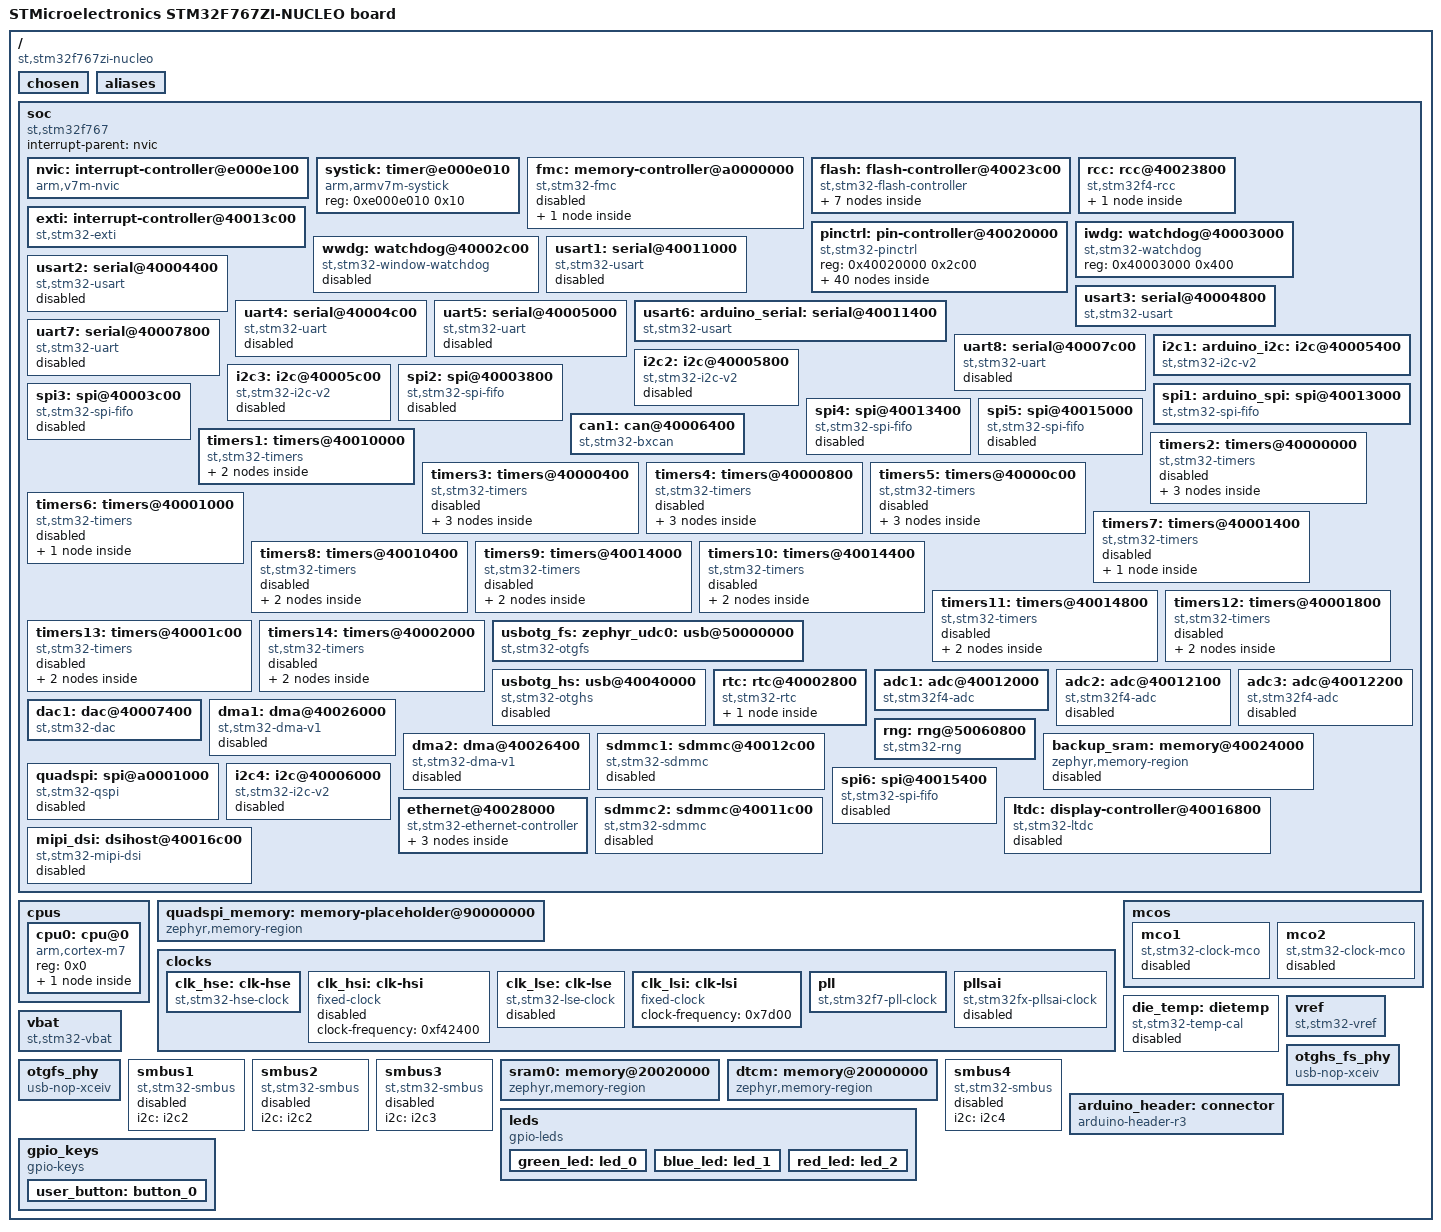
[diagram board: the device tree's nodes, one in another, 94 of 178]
/dts-v1/;

/* node '/' defined in zephyr\dts\common\skeleton.dtsi:9 */
/ {
	#address-cells = < 0x1 >;                              /* in zephyr\dts\common\skeleton.dtsi:10 */
	#size-cells = < 0x1 >;                                 /* in zephyr\dts\common\skeleton.dtsi:11 */
	model = "STMicroelectronics STM32F767ZI-NUCLEO board"; /* in zephyr\boards\st\nucleo_f767zi\nucleo_f767zi.dts:21 */
	compatible = "st,stm32f767zi-nucleo";                  /* in zephyr\boards\st\nucleo_f767zi\nucleo_f767zi.dts:22 */

	/* node '/chosen' defined in zephyr\dts\common\skeleton.dtsi:13 */
	chosen {
		zephyr,entropy = &rng;                    /* in zephyr\dts\arm\st\f7\stm32f7.dtsi:27 */
		zephyr,flash-controller = &flash;         /* in zephyr\dts\arm\st\f7\stm32f7.dtsi:28 */
		zephyr,console = &usart3;                 /* in zephyr\boards\st\nucleo_f767zi\nucleo_f767zi.dts:25 */
		zephyr,shell-uart = &usart3;              /* in zephyr\boards\st\nucleo_f767zi\nucleo_f767zi.dts:26 */
		zephyr,sram = &sram0;                     /* in zephyr\boards\st\nucleo_f767zi\nucleo_f767zi.dts:27 */
		zephyr,flash = &flash0;                   /* in zephyr\boards\st\nucleo_f767zi\nucleo_f767zi.dts:28 */
		zephyr,code-partition = &slot0_partition; /* in zephyr\boards\st\nucleo_f767zi\nucleo_f767zi.dts:29 */
		zephyr,dtcm = &dtcm;                      /* in zephyr\boards\st\nucleo_f767zi\nucleo_f767zi.dts:30 */
		zephyr,canbus = &can1;                    /* in zephyr\boards\st\nucleo_f767zi\nucleo_f767zi.dts:31 */
	};

	/* node '/aliases' defined in zephyr\dts\common\skeleton.dtsi:15 */
	aliases {
		led0 = &green_led;    /* in zephyr\boards\st\nucleo_f767zi\nucleo_f767zi.dts:64 */
		led1 = &blue_led;     /* in zephyr\boards\st\nucleo_f767zi\nucleo_f767zi.dts:65 */
		led2 = &red_led;      /* in zephyr\boards\st\nucleo_f767zi\nucleo_f767zi.dts:66 */
		sw0 = &user_button;   /* in zephyr\boards\st\nucleo_f767zi\nucleo_f767zi.dts:67 */
		watchdog0 = &iwdg;    /* in zephyr\boards\st\nucleo_f767zi\nucleo_f767zi.dts:68 */
		volt-sensor0 = &vref; /* in zephyr\boards\st\nucleo_f767zi\nucleo_f767zi.dts:69 */
		volt-sensor1 = &vbat; /* in zephyr\boards\st\nucleo_f767zi\nucleo_f767zi.dts:70 */
	};

	/* node '/soc' defined in zephyr\dts\arm\armv7-m.dtsi:6 */
	soc {
		#address-cells = < 0x1 >;     /* in zephyr\dts\arm\armv7-m.dtsi:7 */
		#size-cells = < 0x1 >;        /* in zephyr\dts\arm\armv7-m.dtsi:8 */
		interrupt-parent = < &nvic >; /* in zephyr\dts\arm\armv7-m.dtsi:10 */
		ranges;                       /* in zephyr\dts\arm\armv7-m.dtsi:11 */
		compatible = "st,stm32f767",
		             "st,stm32f7",
		             "simple-bus";    /* in zephyr\dts\arm\st\f7\stm32f767.dtsi:13 */

		/* node '/soc/interrupt-controller@e000e100' defined in zephyr\dts\arm\armv7-m.dtsi:13 */
		nvic: interrupt-controller@e000e100 {
			#address-cells = < 0x1 >;            /* in zephyr\dts\arm\armv7-m.dtsi:14 */
			compatible = "arm,v7m-nvic";         /* in zephyr\dts\arm\armv7-m.dtsi:15 */
			reg = < 0xe000e100 0xc00 >;          /* in zephyr\dts\arm\armv7-m.dtsi:16 */
			interrupt-controller;                /* in zephyr\dts\arm\armv7-m.dtsi:17 */
			#interrupt-cells = < 0x2 >;          /* in zephyr\dts\arm\armv7-m.dtsi:18 */
			arm,num-irq-priority-bits = < 0x4 >; /* in zephyr\dts\arm\st\f7\stm32f7.dtsi:991 */
			phandle = < 0x1 >;                   /* in zephyr\dts\arm\armv7-m.dtsi:10 */
		};

		/* node '/soc/timer@e000e010' defined in zephyr\dts\arm\armv7-m.dtsi:21 */
		systick: timer@e000e010 {
			compatible = "arm,armv7m-systick"; /* in zephyr\dts\arm\armv7-m.dtsi:22 */
			reg = < 0xe000e010 0x10 >;         /* in zephyr\dts\arm\armv7-m.dtsi:23 */
		};

		/* node '/soc/memory-controller@a0000000' defined in zephyr\dts\arm\st\f7\stm32f7.dtsi:111 */
		fmc: memory-controller@a0000000 {
			compatible = "st,stm32-fmc"; /* in zephyr\dts\arm\st\f7\stm32f7.dtsi:112 */
			reg = < 0xa0000000 0x400 >;  /* in zephyr\dts\arm\st\f7\stm32f7.dtsi:113 */
			clocks = < &rcc 0x38 0x1 >;  /* in zephyr\dts\arm\st\f7\stm32f7.dtsi:114 */
			status = "disabled";         /* in zephyr\dts\arm\st\f7\stm32f7.dtsi:115 */

			/* node '/soc/memory-controller@a0000000/sdram' defined in zephyr\dts\arm\st\f7\stm32f7.dtsi:117 */
			sdram: sdram {
				compatible = "st,stm32-fmc-sdram"; /* in zephyr\dts\arm\st\f7\stm32f7.dtsi:118 */
				#address-cells = < 0x1 >;          /* in zephyr\dts\arm\st\f7\stm32f7.dtsi:119 */
				#size-cells = < 0x0 >;             /* in zephyr\dts\arm\st\f7\stm32f7.dtsi:120 */
				status = "disabled";               /* in zephyr\dts\arm\st\f7\stm32f7.dtsi:121 */
			};
		};

		/* node '/soc/flash-controller@40023c00' defined in zephyr\dts\arm\st\f7\stm32f7.dtsi:125 */
		flash: flash-controller@40023c00 {
			compatible = "st,stm32-flash-controller",
			             "st,stm32f7-flash-controller"; /* in zephyr\dts\arm\st\f7\stm32f7.dtsi:126 */
			reg = < 0x40023c00 0x400 >;                 /* in zephyr\dts\arm\st\f7\stm32f7.dtsi:127 */
			interrupts = < 0x4 0x0 >;                   /* in zephyr\dts\arm\st\f7\stm32f7.dtsi:128 */
			#address-cells = < 0x1 >;                   /* in zephyr\dts\arm\st\f7\stm32f7.dtsi:130 */
			#size-cells = < 0x1 >;                      /* in zephyr\dts\arm\st\f7\stm32f7.dtsi:131 */

			/* node '/soc/flash-controller@40023c00/flash@8000000' defined in zephyr\dts\arm\st\f7\stm32f7.dtsi:133 */
			flash0: flash@8000000 {
				compatible = "st,stm32-nv-flash",
				             "soc-nv-flash";      /* in zephyr\dts\arm\st\f7\stm32f7.dtsi:134 */
				write-block-size = < 0x1 >;       /* in zephyr\dts\arm\st\f7\stm32f7.dtsi:136 */
				max-erase-time = < 0xfa0 >;       /* in zephyr\dts\arm\st\f7\stm32f7.dtsi:138 */
				reg = < 0x8000000 0x200000 >;     /* in zephyr\dts\arm\st\f7\stm32f767Xi.dtsi:14 */

				/* node '/soc/flash-controller@40023c00/flash@8000000/partitions' defined in zephyr\boards\st\nucleo_f767zi\nucleo_f767zi.dts:219 */
				partitions {
					compatible = "fixed-partitions"; /* in zephyr\boards\st\nucleo_f767zi\nucleo_f767zi.dts:220 */
					#address-cells = < 0x1 >;        /* in zephyr\boards\st\nucleo_f767zi\nucleo_f767zi.dts:221 */
					#size-cells = < 0x1 >;           /* in zephyr\boards\st\nucleo_f767zi\nucleo_f767zi.dts:222 */

					/* node '/soc/flash-controller@40023c00/flash@8000000/partitions/partition@0' defined in zephyr\boards\st\nucleo_f767zi\nucleo_f767zi.dts:228 */
					boot_partition: partition@0 {
						label = "mcuboot";     /* in zephyr\boards\st\nucleo_f767zi\nucleo_f767zi.dts:229 */
						reg = < 0x0 0x10000 >; /* in zephyr\boards\st\nucleo_f767zi\nucleo_f767zi.dts:230 */
						read-only;             /* in zephyr\boards\st\nucleo_f767zi\nucleo_f767zi.dts:231 */
					};

					/* node '/soc/flash-controller@40023c00/flash@8000000/partitions/partition@10000' defined in zephyr\boards\st\nucleo_f767zi\nucleo_f767zi.dts:239 */
					storage_partition: partition@10000 {
						label = "storage";         /* in zephyr\boards\st\nucleo_f767zi\nucleo_f767zi.dts:240 */
						reg = < 0x10000 0x10000 >; /* in zephyr\boards\st\nucleo_f767zi\nucleo_f767zi.dts:241 */
					};

					/* node '/soc/flash-controller@40023c00/flash@8000000/partitions/partition@40000' defined in zephyr\boards\st\nucleo_f767zi\nucleo_f767zi.dts:251 */
					slot0_partition: partition@40000 {
						label = "image-0";         /* in zephyr\boards\st\nucleo_f767zi\nucleo_f767zi.dts:252 */
						reg = < 0x40000 0xc0000 >; /* in zephyr\boards\st\nucleo_f767zi\nucleo_f767zi.dts:253 */
					};

					/* node '/soc/flash-controller@40023c00/flash@8000000/partitions/partition@100000' defined in zephyr\boards\st\nucleo_f767zi\nucleo_f767zi.dts:259 */
					slot1_partition: partition@100000 {
						label = "image-1";          /* in zephyr\boards\st\nucleo_f767zi\nucleo_f767zi.dts:260 */
						reg = < 0x100000 0xc0000 >; /* in zephyr\boards\st\nucleo_f767zi\nucleo_f767zi.dts:261 */
					};

					/* node '/soc/flash-controller@40023c00/flash@8000000/partitions/partition@1C0000' defined in zephyr\boards\st\nucleo_f767zi\nucleo_f767zi.dts:267 */
					scratch_partition: partition@1C0000 {
						label = "image-scratch";    /* in zephyr\boards\st\nucleo_f767zi\nucleo_f767zi.dts:268 */
						reg = < 0x1c0000 0x40000 >; /* in zephyr\boards\st\nucleo_f767zi\nucleo_f767zi.dts:269 */
					};
				};
			};
		};

		/* node '/soc/rcc@40023800' defined in zephyr\dts\arm\st\f7\stm32f7.dtsi:142 */
		rcc: rcc@40023800 {
			compatible = "st,stm32f4-rcc";   /* in zephyr\dts\arm\st\f7\stm32f7.dtsi:143 */
			#clock-cells = < 0x2 >;          /* in zephyr\dts\arm\st\f7\stm32f7.dtsi:144 */
			reg = < 0x40023800 0x400 >;      /* in zephyr\dts\arm\st\f7\stm32f7.dtsi:145 */
			clocks = < &pll >;               /* in zephyr\boards\st\nucleo_f767zi\nucleo_f767zi.dts:94 */
			clock-frequency = < 0xcdfe600 >; /* in zephyr\boards\st\nucleo_f767zi\nucleo_f767zi.dts:95 */
			ahb-prescaler = < 0x1 >;         /* in zephyr\boards\st\nucleo_f767zi\nucleo_f767zi.dts:96 */
			apb1-prescaler = < 0x4 >;        /* in zephyr\boards\st\nucleo_f767zi\nucleo_f767zi.dts:97 */
			apb2-prescaler = < 0x2 >;        /* in zephyr\boards\st\nucleo_f767zi\nucleo_f767zi.dts:98 */
			phandle = < 0x2 >;               /* in zephyr\dts\arm\st\f7\stm32f7.dtsi:114 */

			/* node '/soc/rcc@40023800/reset-controller' defined in zephyr\dts\arm\st\f7\stm32f7.dtsi:147 */
			rctl: reset-controller {
				compatible = "st,stm32-rcc-rctl"; /* in zephyr\dts\arm\st\f7\stm32f7.dtsi:148 */
				#reset-cells = < 0x1 >;           /* in zephyr\dts\arm\st\f7\stm32f7.dtsi:149 */
				phandle = < 0x4 >;                /* in zephyr\dts\arm\st\f7\stm32f7.dtsi:266 */
			};
		};

		/* node '/soc/interrupt-controller@40013c00' defined in zephyr\dts\arm\st\f7\stm32f7.dtsi:153 */
		exti: interrupt-controller@40013c00 {
			compatible = "st,stm32-exti";  /* in zephyr\dts\arm\st\f7\stm32f7.dtsi:154 */
			interrupt-controller;          /* in zephyr\dts\arm\st\f7\stm32f7.dtsi:155 */
			#interrupt-cells = < 0x1 >;    /* in zephyr\dts\arm\st\f7\stm32f7.dtsi:156 */
			#address-cells = < 0x1 >;      /* in zephyr\dts\arm\st\f7\stm32f7.dtsi:157 */
			reg = < 0x40013c00 0x400 >;    /* in zephyr\dts\arm\st\f7\stm32f7.dtsi:158 */
			clocks = < &rcc 0x44 0x4000 >; /* in zephyr\dts\arm\st\f7\stm32f7.dtsi:159 */
			num-lines = < 0x20 >;          /* in zephyr\dts\arm\st\f7\stm32f7.dtsi:160 */
			interrupts = < 0x6 0x0 >,
			             < 0x7 0x0 >,
			             < 0x8 0x0 >,
			             < 0x9 0x0 >,
			             < 0xa 0x0 >,
			             < 0x17 0x0 >,
			             < 0x28 0x0 >;     /* in zephyr\dts\arm\st\f7\stm32f7.dtsi:161 */
			interrupt-names = "line0",
			                  "line1",
			                  "line2",
			                  "line3",
			                  "line4",
			                  "line5-9",
			                  "line10-15"; /* in zephyr\dts\arm\st\f7\stm32f7.dtsi:163 */
			line-ranges = < 0x0 0x1 >,
			              < 0x1 0x1 >,
			              < 0x2 0x1 >,
			              < 0x3 0x1 >,
			              < 0x4 0x1 >,
			              < 0x5 0x5 >,
			              < 0xa 0x6 >;     /* in zephyr\dts\arm\st\f7\stm32f7.dtsi:165 */
		};

		/* node '/soc/pin-controller@40020000' defined in zephyr\dts\arm\st\f7\stm32f7.dtsi:169 */
		pinctrl: pin-controller@40020000 {
			compatible = "st,stm32-pinctrl"; /* in zephyr\dts\arm\st\f7\stm32f7.dtsi:170 */
			#address-cells = < 0x1 >;        /* in zephyr\dts\arm\st\f7\stm32f7.dtsi:171 */
			#size-cells = < 0x1 >;           /* in zephyr\dts\arm\st\f7\stm32f7.dtsi:172 */
			reg = < 0x40020000 0x2c00 >;     /* in zephyr\dts\arm\st\f7\stm32f765.dtsi:30 */

			/* node '/soc/pin-controller@40020000/gpio@40020000' defined in zephyr\dts\arm\st\f7\stm32f7.dtsi:175 */
			gpioa: gpio@40020000 {
				compatible = "st,stm32-gpio"; /* in zephyr\dts\arm\st\f7\stm32f7.dtsi:176 */
				gpio-controller;              /* in zephyr\dts\arm\st\f7\stm32f7.dtsi:177 */
				#gpio-cells = < 0x2 >;        /* in zephyr\dts\arm\st\f7\stm32f7.dtsi:178 */
				reg = < 0x40020000 0x400 >;   /* in zephyr\dts\arm\st\f7\stm32f7.dtsi:179 */
				clocks = < &rcc 0x30 0x1 >;   /* in zephyr\dts\arm\st\f7\stm32f7.dtsi:180 */
				phandle = < 0x2b >;           /* in zephyr\boards\st\nucleo_f767zi\arduino_r3_connector.dtsi:15 */
			};

			/* node '/soc/pin-controller@40020000/gpio@40020400' defined in zephyr\dts\arm\st\f7\stm32f7.dtsi:183 */
			gpiob: gpio@40020400 {
				compatible = "st,stm32-gpio"; /* in zephyr\dts\arm\st\f7\stm32f7.dtsi:184 */
				gpio-controller;              /* in zephyr\dts\arm\st\f7\stm32f7.dtsi:185 */
				#gpio-cells = < 0x2 >;        /* in zephyr\dts\arm\st\f7\stm32f7.dtsi:186 */
				reg = < 0x40020400 0x400 >;   /* in zephyr\dts\arm\st\f7\stm32f7.dtsi:187 */
				clocks = < &rcc 0x30 0x2 >;   /* in zephyr\dts\arm\st\f7\stm32f7.dtsi:188 */
				phandle = < 0x30 >;           /* in zephyr\boards\st\nucleo_f767zi\arduino_r3_connector.dtsi:15 */
			};

			/* node '/soc/pin-controller@40020000/gpio@40020800' defined in zephyr\dts\arm\st\f7\stm32f7.dtsi:191 */
			gpioc: gpio@40020800 {
				compatible = "st,stm32-gpio"; /* in zephyr\dts\arm\st\f7\stm32f7.dtsi:192 */
				gpio-controller;              /* in zephyr\dts\arm\st\f7\stm32f7.dtsi:193 */
				#gpio-cells = < 0x2 >;        /* in zephyr\dts\arm\st\f7\stm32f7.dtsi:194 */
				reg = < 0x40020800 0x400 >;   /* in zephyr\dts\arm\st\f7\stm32f7.dtsi:195 */
				clocks = < &rcc 0x30 0x4 >;   /* in zephyr\dts\arm\st\f7\stm32f7.dtsi:196 */
				phandle = < 0x2c >;           /* in zephyr\boards\st\nucleo_f767zi\arduino_r3_connector.dtsi:15 */
			};

			/* node '/soc/pin-controller@40020000/gpio@40020C00' defined in zephyr\dts\arm\st\f7\stm32f7.dtsi:199 */
			gpiod: gpio@40020C00 {
				compatible = "st,stm32-gpio"; /* in zephyr\dts\arm\st\f7\stm32f7.dtsi:200 */
				gpio-controller;              /* in zephyr\dts\arm\st\f7\stm32f7.dtsi:201 */
				#gpio-cells = < 0x2 >;        /* in zephyr\dts\arm\st\f7\stm32f7.dtsi:202 */
				reg = < 0x40020c00 0x400 >;   /* in zephyr\dts\arm\st\f7\stm32f7.dtsi:203 */
				clocks = < &rcc 0x30 0x8 >;   /* in zephyr\dts\arm\st\f7\stm32f7.dtsi:204 */
				phandle = < 0x12 >;           /* in zephyr\boards\st\nucleo_f767zi\nucleo_f767zi.dts:151 */
			};

			/* node '/soc/pin-controller@40020000/gpio@40021000' defined in zephyr\dts\arm\st\f7\stm32f7.dtsi:207 */
			gpioe: gpio@40021000 {
				compatible = "st,stm32-gpio"; /* in zephyr\dts\arm\st\f7\stm32f7.dtsi:208 */
				gpio-controller;              /* in zephyr\dts\arm\st\f7\stm32f7.dtsi:209 */
				#gpio-cells = < 0x2 >;        /* in zephyr\dts\arm\st\f7\stm32f7.dtsi:210 */
				reg = < 0x40021000 0x400 >;   /* in zephyr\dts\arm\st\f7\stm32f7.dtsi:211 */
				clocks = < &rcc 0x30 0x10 >;  /* in zephyr\dts\arm\st\f7\stm32f7.dtsi:212 */
				phandle = < 0x2f >;           /* in zephyr\boards\st\nucleo_f767zi\arduino_r3_connector.dtsi:15 */
			};

			/* node '/soc/pin-controller@40020000/gpio@40021400' defined in zephyr\dts\arm\st\f7\stm32f7.dtsi:215 */
			gpiof: gpio@40021400 {
				compatible = "st,stm32-gpio"; /* in zephyr\dts\arm\st\f7\stm32f7.dtsi:216 */
				gpio-controller;              /* in zephyr\dts\arm\st\f7\stm32f7.dtsi:217 */
				#gpio-cells = < 0x2 >;        /* in zephyr\dts\arm\st\f7\stm32f7.dtsi:218 */
				reg = < 0x40021400 0x400 >;   /* in zephyr\dts\arm\st\f7\stm32f7.dtsi:219 */
				clocks = < &rcc 0x30 0x20 >;  /* in zephyr\dts\arm\st\f7\stm32f7.dtsi:220 */
				phandle = < 0x2d >;           /* in zephyr\boards\st\nucleo_f767zi\arduino_r3_connector.dtsi:15 */
			};

			/* node '/soc/pin-controller@40020000/gpio@40021800' defined in zephyr\dts\arm\st\f7\stm32f7.dtsi:223 */
			gpiog: gpio@40021800 {
				compatible = "st,stm32-gpio"; /* in zephyr\dts\arm\st\f7\stm32f7.dtsi:224 */
				gpio-controller;              /* in zephyr\dts\arm\st\f7\stm32f7.dtsi:225 */
				#gpio-cells = < 0x2 >;        /* in zephyr\dts\arm\st\f7\stm32f7.dtsi:226 */
				reg = < 0x40021800 0x400 >;   /* in zephyr\dts\arm\st\f7\stm32f7.dtsi:227 */
				clocks = < &rcc 0x30 0x40 >;  /* in zephyr\dts\arm\st\f7\stm32f7.dtsi:228 */
				phandle = < 0x2e >;           /* in zephyr\boards\st\nucleo_f767zi\arduino_r3_connector.dtsi:15 */
			};

			/* node '/soc/pin-controller@40020000/gpio@40021C00' defined in zephyr\dts\arm\st\f7\stm32f7.dtsi:231 */
			gpioh: gpio@40021C00 {
				compatible = "st,stm32-gpio"; /* in zephyr\dts\arm\st\f7\stm32f7.dtsi:232 */
				gpio-controller;              /* in zephyr\dts\arm\st\f7\stm32f7.dtsi:233 */
				#gpio-cells = < 0x2 >;        /* in zephyr\dts\arm\st\f7\stm32f7.dtsi:234 */
				reg = < 0x40021c00 0x400 >;   /* in zephyr\dts\arm\st\f7\stm32f7.dtsi:235 */
				clocks = < &rcc 0x30 0x80 >;  /* in zephyr\dts\arm\st\f7\stm32f7.dtsi:236 */
			};

			/* node '/soc/pin-controller@40020000/gpio@40022000' defined in zephyr\dts\arm\st\f7\stm32f7.dtsi:239 */
			gpioi: gpio@40022000 {
				compatible = "st,stm32-gpio"; /* in zephyr\dts\arm\st\f7\stm32f7.dtsi:240 */
				gpio-controller;              /* in zephyr\dts\arm\st\f7\stm32f7.dtsi:241 */
				#gpio-cells = < 0x2 >;        /* in zephyr\dts\arm\st\f7\stm32f7.dtsi:242 */
				reg = < 0x40022000 0x400 >;   /* in zephyr\dts\arm\st\f7\stm32f7.dtsi:243 */
				clocks = < &rcc 0x30 0x100 >; /* in zephyr\dts\arm\st\f7\stm32f7.dtsi:244 */
			};

			/* node '/soc/pin-controller@40020000/gpio@40022400' defined in zephyr\dts\arm\st\f7\stm32f765.dtsi:32 */
			gpioj: gpio@40022400 {
				compatible = "st,stm32-gpio"; /* in zephyr\dts\arm\st\f7\stm32f765.dtsi:33 */
				gpio-controller;              /* in zephyr\dts\arm\st\f7\stm32f765.dtsi:34 */
				#gpio-cells = < 0x2 >;        /* in zephyr\dts\arm\st\f7\stm32f765.dtsi:35 */
				reg = < 0x40022400 0x400 >;   /* in zephyr\dts\arm\st\f7\stm32f765.dtsi:36 */
				clocks = < &rcc 0x30 0x200 >; /* in zephyr\dts\arm\st\f7\stm32f765.dtsi:37 */
			};

			/* node '/soc/pin-controller@40020000/gpio@40022800' defined in zephyr\dts\arm\st\f7\stm32f765.dtsi:40 */
			gpiok: gpio@40022800 {
				compatible = "st,stm32-gpio"; /* in zephyr\dts\arm\st\f7\stm32f765.dtsi:41 */
				gpio-controller;              /* in zephyr\dts\arm\st\f7\stm32f765.dtsi:42 */
				#gpio-cells = < 0x2 >;        /* in zephyr\dts\arm\st\f7\stm32f765.dtsi:43 */
				reg = < 0x40022800 0x400 >;   /* in zephyr\dts\arm\st\f7\stm32f765.dtsi:44 */
				clocks = < &rcc 0x30 0x400 >; /* in zephyr\dts\arm\st\f7\stm32f765.dtsi:45 */
			};

			/* node '/soc/pin-controller@40020000/adc1_in0_pa0' defined in modules\hal\stm32\dts\st\f7\stm32f767zitx-pinctrl.dtsi:15 */
			adc1_in0_pa0: adc1_in0_pa0 {
				pinmux = < 0x10 >;  /* in modules\hal\stm32\dts\st\f7\stm32f767zitx-pinctrl.dtsi:16 */
				phandle = < 0x1a >; /* in zephyr\boards\st\nucleo_f767zi\nucleo_f767zi.dts:176 */
			};

			/* node '/soc/pin-controller@40020000/can1_rx_pd0' defined in modules\hal\stm32\dts\st\f7\stm32f767zitx-pinctrl.dtsi:677 */
			can1_rx_pd0: can1_rx_pd0 {
				pinmux = < 0x609 >; /* in modules\hal\stm32\dts\st\f7\stm32f767zitx-pinctrl.dtsi:678 */
				bias-pull-up;       /* in modules\hal\stm32\dts\st\f7\stm32f767zitx-pinctrl.dtsi:679 */
				phandle = < 0x13 >; /* in zephyr\boards\st\nucleo_f767zi\nucleo_f767zi.dts:170 */
			};

			/* node '/soc/pin-controller@40020000/can1_tx_pd1' defined in modules\hal\stm32\dts\st\f7\stm32f767zitx-pinctrl.dtsi:712 */
			can1_tx_pd1: can1_tx_pd1 {
				pinmux = < 0x629 >; /* in modules\hal\stm32\dts\st\f7\stm32f767zitx-pinctrl.dtsi:713 */
				phandle = < 0x14 >; /* in zephyr\boards\st\nucleo_f767zi\nucleo_f767zi.dts:170 */
			};

			/* node '/soc/pin-controller@40020000/dac_out1_pa4' defined in modules\hal\stm32\dts\st\f7\stm32f767zitx-pinctrl.dtsi:734 */
			dac_out1_pa4: dac_out1_pa4 {
				pinmux = < 0x90 >;  /* in modules\hal\stm32\dts\st\f7\stm32f767zitx-pinctrl.dtsi:735 */
				phandle = < 0x1b >; /* in zephyr\boards\st\nucleo_f767zi\nucleo_f767zi.dts:185 */
			};

			/* node '/soc/pin-controller@40020000/eth_ref_clk_pa1' defined in modules\hal\stm32\dts\st\f7\stm32f767zitx-pinctrl.dtsi:1168 */
			eth_ref_clk_pa1: eth_ref_clk_pa1 {
				pinmux = < 0x2b >;             /* in modules\hal\stm32\dts\st\f7\stm32f767zitx-pinctrl.dtsi:1169 */
				slew-rate = "very-high-speed"; /* in modules\hal\stm32\dts\st\f7\stm32f767zitx-pinctrl.dtsi:1170 */
				phandle = < 0x1e >;            /* in zephyr\boards\st\nucleo_f767zi\nucleo_f767zi.dts:195 */
			};

			/* node '/soc/pin-controller@40020000/eth_mdio_pa2' defined in modules\hal\stm32\dts\st\f7\stm32f767zitx-pinctrl.dtsi:1178 */
			eth_mdio_pa2: eth_mdio_pa2 {
				pinmux = < 0x4b >;             /* in modules\hal\stm32\dts\st\f7\stm32f767zitx-pinctrl.dtsi:1179 */
				slew-rate = "very-high-speed"; /* in modules\hal\stm32\dts\st\f7\stm32f767zitx-pinctrl.dtsi:1180 */
				phandle = < 0x24 >;            /* in zephyr\boards\st\nucleo_f767zi\nucleo_f767zi.dts:209 */
			};

			/* node '/soc/pin-controller@40020000/eth_crs_dv_pa7' defined in modules\hal\stm32\dts\st\f7\stm32f767zitx-pinctrl.dtsi:1188 */
			eth_crs_dv_pa7: eth_crs_dv_pa7 {
				pinmux = < 0xeb >;             /* in modules\hal\stm32\dts\st\f7\stm32f767zitx-pinctrl.dtsi:1189 */
				slew-rate = "very-high-speed"; /* in modules\hal\stm32\dts\st\f7\stm32f767zitx-pinctrl.dtsi:1190 */
				phandle = < 0x1f >;            /* in zephyr\boards\st\nucleo_f767zi\nucleo_f767zi.dts:195 */
			};

			/* node '/soc/pin-controller@40020000/eth_txd1_pb13' defined in modules\hal\stm32\dts\st\f7\stm32f767zitx-pinctrl.dtsi:1233 */
			eth_txd1_pb13: eth_txd1_pb13 {
				pinmux = < 0x3ab >;            /* in modules\hal\stm32\dts\st\f7\stm32f767zitx-pinctrl.dtsi:1234 */
				slew-rate = "very-high-speed"; /* in modules\hal\stm32\dts\st\f7\stm32f767zitx-pinctrl.dtsi:1235 */
				phandle = < 0x22 >;            /* in zephyr\boards\st\nucleo_f767zi\nucleo_f767zi.dts:195 */
			};

			/* node '/soc/pin-controller@40020000/eth_mdc_pc1' defined in modules\hal\stm32\dts\st\f7\stm32f767zitx-pinctrl.dtsi:1238 */
			eth_mdc_pc1: eth_mdc_pc1 {
				pinmux = < 0x42b >;            /* in modules\hal\stm32\dts\st\f7\stm32f767zitx-pinctrl.dtsi:1239 */
				slew-rate = "very-high-speed"; /* in modules\hal\stm32\dts\st\f7\stm32f767zitx-pinctrl.dtsi:1240 */
				phandle = < 0x25 >;            /* in zephyr\boards\st\nucleo_f767zi\nucleo_f767zi.dts:209 */
			};

			/* node '/soc/pin-controller@40020000/eth_rxd0_pc4' defined in modules\hal\stm32\dts\st\f7\stm32f767zitx-pinctrl.dtsi:1253 */
			eth_rxd0_pc4: eth_rxd0_pc4 {
				pinmux = < 0x48b >;            /* in modules\hal\stm32\dts\st\f7\stm32f767zitx-pinctrl.dtsi:1254 */
				slew-rate = "very-high-speed"; /* in modules\hal\stm32\dts\st\f7\stm32f767zitx-pinctrl.dtsi:1255 */
				phandle = < 0x1c >;            /* in zephyr\boards\st\nucleo_f767zi\nucleo_f767zi.dts:195 */
			};

			/* node '/soc/pin-controller@40020000/eth_rxd1_pc5' defined in modules\hal\stm32\dts\st\f7\stm32f767zitx-pinctrl.dtsi:1258 */
			eth_rxd1_pc5: eth_rxd1_pc5 {
				pinmux = < 0x4ab >;            /* in modules\hal\stm32\dts\st\f7\stm32f767zitx-pinctrl.dtsi:1259 */
				slew-rate = "very-high-speed"; /* in modules\hal\stm32\dts\st\f7\stm32f767zitx-pinctrl.dtsi:1260 */
				phandle = < 0x1d >;            /* in zephyr\boards\st\nucleo_f767zi\nucleo_f767zi.dts:195 */
			};

			/* node '/soc/pin-controller@40020000/eth_tx_en_pg11' defined in modules\hal\stm32\dts\st\f7\stm32f767zitx-pinctrl.dtsi:1273 */
			eth_tx_en_pg11: eth_tx_en_pg11 {
				pinmux = < 0xd6b >;            /* in modules\hal\stm32\dts\st\f7\stm32f767zitx-pinctrl.dtsi:1274 */
				slew-rate = "very-high-speed"; /* in modules\hal\stm32\dts\st\f7\stm32f767zitx-pinctrl.dtsi:1275 */
				phandle = < 0x20 >;            /* in zephyr\boards\st\nucleo_f767zi\nucleo_f767zi.dts:195 */
			};

			/* node '/soc/pin-controller@40020000/eth_txd0_pg13' defined in modules\hal\stm32\dts\st\f7\stm32f767zitx-pinctrl.dtsi:1278 */
			eth_txd0_pg13: eth_txd0_pg13 {
				pinmux = < 0xdab >;            /* in modules\hal\stm32\dts\st\f7\stm32f767zitx-pinctrl.dtsi:1279 */
				slew-rate = "very-high-speed"; /* in modules\hal\stm32\dts\st\f7\stm32f767zitx-pinctrl.dtsi:1280 */
				phandle = < 0x21 >;            /* in zephyr\boards\st\nucleo_f767zi\nucleo_f767zi.dts:195 */
			};

			/* node '/soc/pin-controller@40020000/i2c1_scl_pb8' defined in modules\hal\stm32\dts\st\f7\stm32f767zitx-pinctrl.dtsi:1724 */
			i2c1_scl_pb8: i2c1_scl_pb8 {
				pinmux = < 0x304 >; /* in modules\hal\stm32\dts\st\f7\stm32f767zitx-pinctrl.dtsi:1725 */
				bias-pull-up;       /* in modules\hal\stm32\dts\st\f7\stm32f767zitx-pinctrl.dtsi:1726 */
				drive-open-drain;   /* in modules\hal\stm32\dts\st\f7\stm32f767zitx-pinctrl.dtsi:1727 */
				phandle = < 0xd >;  /* in zephyr\boards\st\nucleo_f767zi\nucleo_f767zi.dts:131 */
			};

			/* node '/soc/pin-controller@40020000/i2c1_sda_pb9' defined in modules\hal\stm32\dts\st\f7\stm32f767zitx-pinctrl.dtsi:1780 */
			i2c1_sda_pb9: i2c1_sda_pb9 {
				pinmux = < 0x324 >; /* in modules\hal\stm32\dts\st\f7\stm32f767zitx-pinctrl.dtsi:1781 */
				bias-pull-up;       /* in modules\hal\stm32\dts\st\f7\stm32f767zitx-pinctrl.dtsi:1782 */
				drive-open-drain;   /* in modules\hal\stm32\dts\st\f7\stm32f767zitx-pinctrl.dtsi:1783 */
				phandle = < 0xe >;  /* in zephyr\boards\st\nucleo_f767zi\nucleo_f767zi.dts:131 */
			};

			/* node '/soc/pin-controller@40020000/spi1_miso_pa6' defined in modules\hal\stm32\dts\st\f7\stm32f767zitx-pinctrl.dtsi:2636 */
			spi1_miso_pa6: spi1_miso_pa6 {
				pinmux = < 0xc5 >;  /* in modules\hal\stm32\dts\st\f7\stm32f767zitx-pinctrl.dtsi:2637 */
				bias-pull-down;     /* in modules\hal\stm32\dts\st\f7\stm32f767zitx-pinctrl.dtsi:2638 */
				phandle = < 0x10 >; /* in zephyr\boards\st\nucleo_f767zi\nucleo_f767zi.dts:149 */
			};

			/* node '/soc/pin-controller@40020000/spi1_mosi_pa7' defined in modules\hal\stm32\dts\st\f7\stm32f767zitx-pinctrl.dtsi:2703 */
			spi1_mosi_pa7: spi1_mosi_pa7 {
				pinmux = < 0xe5 >;  /* in modules\hal\stm32\dts\st\f7\stm32f767zitx-pinctrl.dtsi:2704 */
				bias-pull-down;     /* in modules\hal\stm32\dts\st\f7\stm32f767zitx-pinctrl.dtsi:2705 */
				phandle = < 0x11 >; /* in zephyr\boards\st\nucleo_f767zi\nucleo_f767zi.dts:149 */
			};

			/* node '/soc/pin-controller@40020000/spi1_sck_pa5' defined in modules\hal\stm32\dts\st\f7\stm32f767zitx-pinctrl.dtsi:2867 */
			spi1_sck_pa5: spi1_sck_pa5 {
				pinmux = < 0xa5 >;             /* in modules\hal\stm32\dts\st\f7\stm32f767zitx-pinctrl.dtsi:2868 */
				bias-pull-down;                /* in modules\hal\stm32\dts\st\f7\stm32f767zitx-pinctrl.dtsi:2869 */
				slew-rate = "very-high-speed"; /* in modules\hal\stm32\dts\st\f7\stm32f767zitx-pinctrl.dtsi:2870 */
				phandle = < 0xf >;             /* in zephyr\boards\st\nucleo_f767zi\nucleo_f767zi.dts:149 */
			};

			/* node '/soc/pin-controller@40020000/tim1_ch3_pe13' defined in modules\hal\stm32\dts\st\f7\stm32f767zitx-pinctrl.dtsi:3063 */
			tim1_ch3_pe13: tim1_ch3_pe13 {
				pinmux = < 0x9a1 >; /* in modules\hal\stm32\dts\st\f7\stm32f767zitx-pinctrl.dtsi:3064 */
				phandle = < 0x15 >; /* in zephyr\boards\st\nucleo_f767zi\nucleo_f767zi.dts:143 */
			};

			/* node '/soc/pin-controller@40020000/usart2_cts_pd3' defined in modules\hal\stm32\dts\st\f7\stm32f767zitx-pinctrl.dtsi:3291 */
			usart2_cts_pd3: usart2_cts_pd3 {
				pinmux = < 0x667 >; /* in modules\hal\stm32\dts\st\f7\stm32f767zitx-pinctrl.dtsi:3292 */
				bias-pull-up;       /* in modules\hal\stm32\dts\st\f7\stm32f767zitx-pinctrl.dtsi:3293 */
				phandle = < 0x8 >;  /* in zephyr\boards\st\nucleo_f767zi\nucleo_f767zi.dts:102 */
			};

			/* node '/soc/pin-controller@40020000/usart2_rts_pd4' defined in modules\hal\stm32\dts\st\f7\stm32f767zitx-pinctrl.dtsi:3425 */
			usart2_rts_pd4: usart2_rts_pd4 {
				pinmux = < 0x687 >; /* in modules\hal\stm32\dts\st\f7\stm32f767zitx-pinctrl.dtsi:3426 */
				drive-push-pull;    /* in modules\hal\stm32\dts\st\f7\stm32f767zitx-pinctrl.dtsi:3427 */
				phandle = < 0x7 >;  /* in zephyr\boards\st\nucleo_f767zi\nucleo_f767zi.dts:102 */
			};

			/* node '/soc/pin-controller@40020000/usart2_rx_pd6' defined in modules\hal\stm32\dts\st\f7\stm32f767zitx-pinctrl.dtsi:3498 */
			usart2_rx_pd6: usart2_rx_pd6 {
				pinmux = < 0x6c7 >; /* in modules\hal\stm32\dts\st\f7\stm32f767zitx-pinctrl.dtsi:3499 */
				phandle = < 0x6 >;  /* in zephyr\boards\st\nucleo_f767zi\nucleo_f767zi.dts:102 */
			};

			/* node '/soc/pin-controller@40020000/usart3_rx_pd9' defined in modules\hal\stm32\dts\st\f7\stm32f767zitx-pinctrl.dtsi:3510 */
			usart3_rx_pd9: usart3_rx_pd9 {
				pinmux = < 0x727 >; /* in modules\hal\stm32\dts\st\f7\stm32f767zitx-pinctrl.dtsi:3511 */
				phandle = < 0xa >;  /* in zephyr\boards\st\nucleo_f767zi\nucleo_f767zi.dts:111 */
			};

			/* node '/soc/pin-controller@40020000/usart6_rx_pg9' defined in modules\hal\stm32\dts\st\f7\stm32f767zitx-pinctrl.dtsi:3550 */
			usart6_rx_pg9: usart6_rx_pg9 {
				pinmux = < 0xd28 >; /* in modules\hal\stm32\dts\st\f7\stm32f767zitx-pinctrl.dtsi:3551 */
				phandle = < 0xc >;  /* in zephyr\boards\st\nucleo_f767zi\nucleo_f767zi.dts:118 */
			};

			/* node '/soc/pin-controller@40020000/usart2_tx_pd5' defined in modules\hal\stm32\dts\st\f7\stm32f767zitx-pinctrl.dtsi:3596 */
			usart2_tx_pd5: usart2_tx_pd5 {
				pinmux = < 0x6a7 >; /* in modules\hal\stm32\dts\st\f7\stm32f767zitx-pinctrl.dtsi:3597 */
				bias-pull-up;       /* in modules\hal\stm32\dts\st\f7\stm32f767zitx-pinctrl.dtsi:3598 */
				phandle = < 0x5 >;  /* in zephyr\boards\st\nucleo_f767zi\nucleo_f767zi.dts:102 */
			};

			/* node '/soc/pin-controller@40020000/usart3_tx_pd8' defined in modules\hal\stm32\dts\st\f7\stm32f767zitx-pinctrl.dtsi:3611 */
			usart3_tx_pd8: usart3_tx_pd8 {
				pinmux = < 0x707 >; /* in modules\hal\stm32\dts\st\f7\stm32f767zitx-pinctrl.dtsi:3612 */
				bias-pull-up;       /* in modules\hal\stm32\dts\st\f7\stm32f767zitx-pinctrl.dtsi:3613 */
				phandle = < 0x9 >;  /* in zephyr\boards\st\nucleo_f767zi\nucleo_f767zi.dts:111 */
			};

			/* node '/soc/pin-controller@40020000/usart6_tx_pg14' defined in modules\hal\stm32\dts\st\f7\stm32f767zitx-pinctrl.dtsi:3661 */
			usart6_tx_pg14: usart6_tx_pg14 {
				pinmux = < 0xdc8 >; /* in modules\hal\stm32\dts\st\f7\stm32f767zitx-pinctrl.dtsi:3662 */
				bias-pull-up;       /* in modules\hal\stm32\dts\st\f7\stm32f767zitx-pinctrl.dtsi:3663 */
				phandle = < 0xb >;  /* in zephyr\boards\st\nucleo_f767zi\nucleo_f767zi.dts:118 */
			};

			/* node '/soc/pin-controller@40020000/usb_otg_fs_dm_pa11' defined in modules\hal\stm32\dts\st\f7\stm32f767zitx-pinctrl.dtsi:3705 */
			usb_otg_fs_dm_pa11: usb_otg_fs_dm_pa11 {
				pinmux = < 0x16a >; /* in modules\hal\stm32\dts\st\f7\stm32f767zitx-pinctrl.dtsi:3706 */
				phandle = < 0x17 >; /* in zephyr\boards\st\nucleo_f767zi\nucleo_f767zi.dts:125 */
			};

			/* node '/soc/pin-controller@40020000/usb_otg_fs_dp_pa12' defined in modules\hal\stm32\dts\st\f7\stm32f767zitx-pinctrl.dtsi:3709 */
			usb_otg_fs_dp_pa12: usb_otg_fs_dp_pa12 {
				pinmux = < 0x18a >; /* in modules\hal\stm32\dts\st\f7\stm32f767zitx-pinctrl.dtsi:3710 */
				phandle = < 0x18 >; /* in zephyr\boards\st\nucleo_f767zi\nucleo_f767zi.dts:125 */
			};
		};

		/* node '/soc/watchdog@40003000' defined in zephyr\dts\arm\st\f7\stm32f7.dtsi:248 */
		iwdg: watchdog@40003000 {
			compatible = "st,stm32-watchdog"; /* in zephyr\dts\arm\st\f7\stm32f7.dtsi:249 */
			reg = < 0x40003000 0x400 >;       /* in zephyr\dts\arm\st\f7\stm32f7.dtsi:250 */
			status = "okay";                  /* in zephyr\boards\st\nucleo_f767zi\nucleo_f767zi.dts:160 */
		};

		/* node '/soc/watchdog@40002c00' defined in zephyr\dts\arm\st\f7\stm32f7.dtsi:254 */
		wwdg: watchdog@40002c00 {
			compatible = "st,stm32-window-watchdog"; /* in zephyr\dts\arm\st\f7\stm32f7.dtsi:255 */
			reg = < 0x40002c00 0x400 >;              /* in zephyr\dts\arm\st\f7\stm32f7.dtsi:256 */
			clocks = < &rcc 0x40 0x800 >;            /* in zephyr\dts\arm\st\f7\stm32f7.dtsi:257 */
			interrupts = < 0x0 0x7 >;                /* in zephyr\dts\arm\st\f7\stm32f7.dtsi:258 */
			status = "disabled";                     /* in zephyr\dts\arm\st\f7\stm32f7.dtsi:259 */
		};

		/* node '/soc/serial@40011000' defined in zephyr\dts\arm\st\f7\stm32f7.dtsi:262 */
		usart1: serial@40011000 {
			compatible = "st,stm32-usart",
			             "st,stm32-uart";  /* in zephyr\dts\arm\st\f7\stm32f7.dtsi:263 */
			reg = < 0x40011000 0x400 >;    /* in zephyr\dts\arm\st\f7\stm32f7.dtsi:264 */
			clocks = < &rcc 0x44 0x10 >;   /* in zephyr\dts\arm\st\f7\stm32f7.dtsi:265 */
			resets = < &rctl 0x484 >;      /* in zephyr\dts\arm\st\f7\stm32f7.dtsi:266 */
			interrupts = < 0x25 0x0 >;     /* in zephyr\dts\arm\st\f7\stm32f7.dtsi:267 */
			status = "disabled";           /* in zephyr\dts\arm\st\f7\stm32f7.dtsi:268 */
		};

		/* node '/soc/serial@40004400' defined in zephyr\dts\arm\st\f7\stm32f7.dtsi:271 */
		usart2: serial@40004400 {
			compatible = "st,stm32-usart",
			             "st,stm32-uart";                                                  /* in zephyr\dts\arm\st\f7\stm32f7.dtsi:272 */
			reg = < 0x40004400 0x400 >;                                                    /* in zephyr\dts\arm\st\f7\stm32f7.dtsi:273 */
			clocks = < &rcc 0x40 0x20000 >;                                                /* in zephyr\dts\arm\st\f7\stm32f7.dtsi:274 */
			resets = < &rctl 0x411 >;                                                      /* in zephyr\dts\arm\st\f7\stm32f7.dtsi:275 */
			interrupts = < 0x26 0x0 >;                                                     /* in zephyr\dts\arm\st\f7\stm32f7.dtsi:276 */
			status = "disabled";                                                           /* in zephyr\dts\arm\st\f7\stm32f7.dtsi:277 */
			pinctrl-0 = < &usart2_tx_pd5 &usart2_rx_pd6 &usart2_rts_pd4 &usart2_cts_pd3 >; /* in zephyr\boards\st\nucleo_f767zi\nucleo_f767zi.dts:102 */
			pinctrl-names = "default";                                                     /* in zephyr\boards\st\nucleo_f767zi\nucleo_f767zi.dts:106 */
			current-speed = < 0x1c200 >;                                                   /* in zephyr\boards\st\nucleo_f767zi\nucleo_f767zi.dts:107 */
		};

		/* node '/soc/serial@40004800' defined in zephyr\dts\arm\st\f7\stm32f7.dtsi:280 */
		usart3: serial@40004800 {
			compatible = "st,stm32-usart",
			             "st,stm32-uart";                  /* in zephyr\dts\arm\st\f7\stm32f7.dtsi:281 */
			reg = < 0x40004800 0x400 >;                    /* in zephyr\dts\arm\st\f7\stm32f7.dtsi:282 */
			clocks = < &rcc 0x40 0x40000 >;                /* in zephyr\dts\arm\st\f7\stm32f7.dtsi:283 */
			resets = < &rctl 0x412 >;                      /* in zephyr\dts\arm\st\f7\stm32f7.dtsi:284 */
			interrupts = < 0x27 0x0 >;                     /* in zephyr\dts\arm\st\f7\stm32f7.dtsi:285 */
			pinctrl-0 = < &usart3_tx_pd8 &usart3_rx_pd9 >; /* in zephyr\boards\st\nucleo_f767zi\nucleo_f767zi.dts:111 */
			pinctrl-names = "default";                     /* in zephyr\boards\st\nucleo_f767zi\nucleo_f767zi.dts:112 */
			current-speed = < 0x1c200 >;                   /* in zephyr\boards\st\nucleo_f767zi\nucleo_f767zi.dts:113 */
			status = "okay";                               /* in zephyr\boards\st\nucleo_f767zi\nucleo_f767zi.dts:114 */
		};

		/* node '/soc/serial@40004c00' defined in zephyr\dts\arm\st\f7\stm32f7.dtsi:289 */
		uart4: serial@40004c00 {
			compatible = "st,stm32-uart";   /* in zephyr\dts\arm\st\f7\stm32f7.dtsi:290 */
			reg = < 0x40004c00 0x400 >;     /* in zephyr\dts\arm\st\f7\stm32f7.dtsi:291 */
			clocks = < &rcc 0x40 0x80000 >; /* in zephyr\dts\arm\st\f7\stm32f7.dtsi:292 */
			resets = < &rctl 0x413 >;       /* in zephyr\dts\arm\st\f7\stm32f7.dtsi:293 */
			interrupts = < 0x34 0x0 >;      /* in zephyr\dts\arm\st\f7\stm32f7.dtsi:294 */
			status = "disabled";            /* in zephyr\dts\arm\st\f7\stm32f7.dtsi:295 */
		};

		/* node '/soc/serial@40005000' defined in zephyr\dts\arm\st\f7\stm32f7.dtsi:298 */
		uart5: serial@40005000 {
			compatible = "st,stm32-uart";    /* in zephyr\dts\arm\st\f7\stm32f7.dtsi:299 */
			reg = < 0x40005000 0x400 >;      /* in zephyr\dts\arm\st\f7\stm32f7.dtsi:300 */
			clocks = < &rcc 0x40 0x100000 >; /* in zephyr\dts\arm\st\f7\stm32f7.dtsi:301 */
			resets = < &rctl 0x414 >;        /* in zephyr\dts\arm\st\f7\stm32f7.dtsi:302 */
			interrupts = < 0x35 0x0 >;       /* in zephyr\dts\arm\st\f7\stm32f7.dtsi:303 */
			status = "disabled";             /* in zephyr\dts\arm\st\f7\stm32f7.dtsi:304 */
		};

		/* node '/soc/serial@40011400' defined in zephyr\dts\arm\st\f7\stm32f7.dtsi:307 */
		usart6: arduino_serial: serial@40011400 {
			compatible = "st,stm32-usart",
			             "st,stm32-uart";                   /* in zephyr\dts\arm\st\f7\stm32f7.dtsi:308 */
			reg = < 0x40011400 0x400 >;                     /* in zephyr\dts\arm\st\f7\stm32f7.dtsi:309 */
			clocks = < &rcc 0x44 0x20 >;                    /* in zephyr\dts\arm\st\f7\stm32f7.dtsi:310 */
			resets = < &rctl 0x485 >;                       /* in zephyr\dts\arm\st\f7\stm32f7.dtsi:311 */
			interrupts = < 0x47 0x0 >;                      /* in zephyr\dts\arm\st\f7\stm32f7.dtsi:312 */
			pinctrl-0 = < &usart6_tx_pg14 &usart6_rx_pg9 >; /* in zephyr\boards\st\nucleo_f767zi\nucleo_f767zi.dts:118 */
			pinctrl-names = "default";                      /* in zephyr\boards\st\nucleo_f767zi\nucleo_f767zi.dts:119 */
			current-speed = < 0x1c200 >;                    /* in zephyr\boards\st\nucleo_f767zi\nucleo_f767zi.dts:120 */
			status = "okay";                                /* in zephyr\boards\st\nucleo_f767zi\nucleo_f767zi.dts:121 */
		};

		/* node '/soc/serial@40007800' defined in zephyr\dts\arm\st\f7\stm32f7.dtsi:316 */
		uart7: serial@40007800 {
			compatible = "st,stm32-uart";      /* in zephyr\dts\arm\st\f7\stm32f7.dtsi:317 */
			reg = < 0x40007800 0x400 >;        /* in zephyr\dts\arm\st\f7\stm32f7.dtsi:318 */
			clocks = < &rcc 0x40 0x40000000 >; /* in zephyr\dts\arm\st\f7\stm32f7.dtsi:319 */
			resets = < &rctl 0x41e >;          /* in zephyr\dts\arm\st\f7\stm32f7.dtsi:320 */
			interrupts = < 0x52 0x0 >;         /* in zephyr\dts\arm\st\f7\stm32f7.dtsi:321 */
			status = "disabled";               /* in zephyr\dts\arm\st\f7\stm32f7.dtsi:322 */
		};

		/* node '/soc/serial@40007c00' defined in zephyr\dts\arm\st\f7\stm32f7.dtsi:325 */
		uart8: serial@40007c00 {
			compatible = "st,stm32-uart";      /* in zephyr\dts\arm\st\f7\stm32f7.dtsi:326 */
			reg = < 0x40007c00 0x400 >;        /* in zephyr\dts\arm\st\f7\stm32f7.dtsi:327 */
			clocks = < &rcc 0x40 0x80000000 >; /* in zephyr\dts\arm\st\f7\stm32f7.dtsi:328 */
			resets = < &rctl 0x41f >;          /* in zephyr\dts\arm\st\f7\stm32f7.dtsi:329 */
			interrupts = < 0x53 0x0 >;         /* in zephyr\dts\arm\st\f7\stm32f7.dtsi:330 */
			status = "disabled";               /* in zephyr\dts\arm\st\f7\stm32f7.dtsi:331 */
		};

		/* node '/soc/i2c@40005400' defined in zephyr\dts\arm\st\f7\stm32f7.dtsi:334 */
		i2c1: arduino_i2c: i2c@40005400 {
			compatible = "st,stm32-i2c-v2";              /* in zephyr\dts\arm\st\f7\stm32f7.dtsi:335 */
			#address-cells = < 0x1 >;                    /* in zephyr\dts\arm\st\f7\stm32f7.dtsi:337 */
			#size-cells = < 0x0 >;                       /* in zephyr\dts\arm\st\f7\stm32f7.dtsi:338 */
			reg = < 0x40005400 0x400 >;                  /* in zephyr\dts\arm\st\f7\stm32f7.dtsi:339 */
			clocks = < &rcc 0x40 0x200000 >;             /* in zephyr\dts\arm\st\f7\stm32f7.dtsi:340 */
			interrupts = < 0x1f 0x0 >,
			             < 0x20 0x0 >;                   /* in zephyr\dts\arm\st\f7\stm32f7.dtsi:341 */
			interrupt-names = "event",
			                  "error";                   /* in zephyr\dts\arm\st\f7\stm32f7.dtsi:342 */
			pinctrl-0 = < &i2c1_scl_pb8 &i2c1_sda_pb9 >; /* in zephyr\boards\st\nucleo_f767zi\nucleo_f767zi.dts:131 */
			pinctrl-names = "default";                   /* in zephyr\boards\st\nucleo_f767zi\nucleo_f767zi.dts:132 */
			status = "okay";                             /* in zephyr\boards\st\nucleo_f767zi\nucleo_f767zi.dts:133 */
			clock-frequency = < 0x61a80 >;               /* in zephyr\boards\st\nucleo_f767zi\nucleo_f767zi.dts:134 */
		};

		/* node '/soc/i2c@40005800' defined in zephyr\dts\arm\st\f7\stm32f7.dtsi:346 */
		i2c2: i2c@40005800 {
			compatible = "st,stm32-i2c-v2";  /* in zephyr\dts\arm\st\f7\stm32f7.dtsi:347 */
			clock-frequency = < 0x186a0 >;   /* in zephyr\dts\arm\st\f7\stm32f7.dtsi:348 */
			#address-cells = < 0x1 >;        /* in zephyr\dts\arm\st\f7\stm32f7.dtsi:349 */
			#size-cells = < 0x0 >;           /* in zephyr\dts\arm\st\f7\stm32f7.dtsi:350 */
			reg = < 0x40005800 0x400 >;      /* in zephyr\dts\arm\st\f7\stm32f7.dtsi:351 */
			clocks = < &rcc 0x40 0x400000 >; /* in zephyr\dts\arm\st\f7\stm32f7.dtsi:352 */
			interrupts = < 0x21 0x0 >,
			             < 0x22 0x0 >;       /* in zephyr\dts\arm\st\f7\stm32f7.dtsi:353 */
			interrupt-names = "event",
			                  "error";       /* in zephyr\dts\arm\st\f7\stm32f7.dtsi:354 */
			status = "disabled";             /* in zephyr\dts\arm\st\f7\stm32f7.dtsi:355 */
			phandle = < 0x28 >;              /* in zephyr\dts\arm\st\f7\stm32f7.dtsi:969 */
		};

		/* node '/soc/i2c@40005c00' defined in zephyr\dts\arm\st\f7\stm32f7.dtsi:358 */
		i2c3: i2c@40005c00 {
			compatible = "st,stm32-i2c-v2";  /* in zephyr\dts\arm\st\f7\stm32f7.dtsi:359 */
			clock-frequency = < 0x186a0 >;   /* in zephyr\dts\arm\st\f7\stm32f7.dtsi:360 */
			#address-cells = < 0x1 >;        /* in zephyr\dts\arm\st\f7\stm32f7.dtsi:361 */
			#size-cells = < 0x0 >;           /* in zephyr\dts\arm\st\f7\stm32f7.dtsi:362 */
			reg = < 0x40005c00 0x400 >;      /* in zephyr\dts\arm\st\f7\stm32f7.dtsi:363 */
			clocks = < &rcc 0x40 0x800000 >; /* in zephyr\dts\arm\st\f7\stm32f7.dtsi:364 */
			interrupts = < 0x48 0x0 >,
			             < 0x49 0x0 >;       /* in zephyr\dts\arm\st\f7\stm32f7.dtsi:365 */
			interrupt-names = "event",
			                  "error";       /* in zephyr\dts\arm\st\f7\stm32f7.dtsi:366 */
			status = "disabled";             /* in zephyr\dts\arm\st\f7\stm32f7.dtsi:367 */
			phandle = < 0x29 >;              /* in zephyr\dts\arm\st\f7\stm32f7.dtsi:985 */
		};

		/* node '/soc/spi@40013000' defined in zephyr\dts\arm\st\f7\stm32f7.dtsi:370 */
		spi1: arduino_spi: spi@40013000 {
			compatible = "st,stm32-spi-fifo",
			             "st,stm32-spi";                                 /* in zephyr\dts\arm\st\f7\stm32f7.dtsi:371 */
			#address-cells = < 0x1 >;                                    /* in zephyr\dts\arm\st\f7\stm32f7.dtsi:372 */
			#size-cells = < 0x0 >;                                       /* in zephyr\dts\arm\st\f7\stm32f7.dtsi:373 */
			reg = < 0x40013000 0x400 >;                                  /* in zephyr\dts\arm\st\f7\stm32f7.dtsi:374 */
			clocks = < &rcc 0x44 0x1000 >;                               /* in zephyr\dts\arm\st\f7\stm32f7.dtsi:375 */
			interrupts = < 0x23 0x5 >;                                   /* in zephyr\dts\arm\st\f7\stm32f7.dtsi:376 */
			pinctrl-0 = < &spi1_sck_pa5 &spi1_miso_pa6 &spi1_mosi_pa7 >; /* in zephyr\boards\st\nucleo_f767zi\nucleo_f767zi.dts:149 */
			pinctrl-names = "default";                                   /* in zephyr\boards\st\nucleo_f767zi\nucleo_f767zi.dts:150 */
			cs-gpios = < &gpiod 0xe 0x11 >;                              /* in zephyr\boards\st\nucleo_f767zi\nucleo_f767zi.dts:151 */
			status = "okay";                                             /* in zephyr\boards\st\nucleo_f767zi\nucleo_f767zi.dts:156 */
		};

		/* node '/soc/spi@40003800' defined in zephyr\dts\arm\st\f7\stm32f7.dtsi:380 */
		spi2: spi@40003800 {
			compatible = "st,stm32-spi-fifo",
			             "st,stm32-spi";      /* in zephyr\dts\arm\st\f7\stm32f7.dtsi:381 */
			#address-cells = < 0x1 >;         /* in zephyr\dts\arm\st\f7\stm32f7.dtsi:382 */
			#size-cells = < 0x0 >;            /* in zephyr\dts\arm\st\f7\stm32f7.dtsi:383 */
			reg = < 0x40003800 0x400 >;       /* in zephyr\dts\arm\st\f7\stm32f7.dtsi:384 */
			clocks = < &rcc 0x40 0x4000 >;    /* in zephyr\dts\arm\st\f7\stm32f7.dtsi:385 */
			interrupts = < 0x24 0x5 >;        /* in zephyr\dts\arm\st\f7\stm32f7.dtsi:386 */
			status = "disabled";              /* in zephyr\dts\arm\st\f7\stm32f7.dtsi:387 */
		};

		/* node '/soc/spi@40003c00' defined in zephyr\dts\arm\st\f7\stm32f7.dtsi:390 */
		spi3: spi@40003c00 {
			compatible = "st,stm32-spi-fifo",
			             "st,stm32-spi";      /* in zephyr\dts\arm\st\f7\stm32f7.dtsi:391 */
			#address-cells = < 0x1 >;         /* in zephyr\dts\arm\st\f7\stm32f7.dtsi:392 */
			#size-cells = < 0x0 >;            /* in zephyr\dts\arm\st\f7\stm32f7.dtsi:393 */
			reg = < 0x40003c00 0x400 >;       /* in zephyr\dts\arm\st\f7\stm32f7.dtsi:394 */
			clocks = < &rcc 0x40 0x8000 >;    /* in zephyr\dts\arm\st\f7\stm32f7.dtsi:395 */
			interrupts = < 0x33 0x5 >;        /* in zephyr\dts\arm\st\f7\stm32f7.dtsi:396 */
			status = "disabled";              /* in zephyr\dts\arm\st\f7\stm32f7.dtsi:397 */
		};

		/* node '/soc/spi@40013400' defined in zephyr\dts\arm\st\f7\stm32f7.dtsi:400 */
		spi4: spi@40013400 {
			compatible = "st,stm32-spi-fifo",
			             "st,stm32-spi";      /* in zephyr\dts\arm\st\f7\stm32f7.dtsi:401 */
			#address-cells = < 0x1 >;         /* in zephyr\dts\arm\st\f7\stm32f7.dtsi:402 */
			#size-cells = < 0x0 >;            /* in zephyr\dts\arm\st\f7\stm32f7.dtsi:403 */
			reg = < 0x40013400 0x400 >;       /* in zephyr\dts\arm\st\f7\stm32f7.dtsi:404 */
			clocks = < &rcc 0x44 0x2000 >;    /* in zephyr\dts\arm\st\f7\stm32f7.dtsi:405 */
			interrupts = < 0x54 0x5 >;        /* in zephyr\dts\arm\st\f7\stm32f7.dtsi:406 */
			status = "disabled";              /* in zephyr\dts\arm\st\f7\stm32f7.dtsi:407 */
		};

		/* node '/soc/spi@40015000' defined in zephyr\dts\arm\st\f7\stm32f7.dtsi:410 */
		spi5: spi@40015000 {
			compatible = "st,stm32-spi-fifo",
			             "st,stm32-spi";      /* in zephyr\dts\arm\st\f7\stm32f7.dtsi:411 */
			#address-cells = < 0x1 >;         /* in zephyr\dts\arm\st\f7\stm32f7.dtsi:412 */
			#size-cells = < 0x0 >;            /* in zephyr\dts\arm\st\f7\stm32f7.dtsi:413 */
			reg = < 0x40015000 0x400 >;       /* in zephyr\dts\arm\st\f7\stm32f7.dtsi:414 */
			clocks = < &rcc 0x44 0x100000 >;  /* in zephyr\dts\arm\st\f7\stm32f7.dtsi:415 */
			interrupts = < 0x55 0x5 >;        /* in zephyr\dts\arm\st\f7\stm32f7.dtsi:416 */
			status = "disabled";              /* in zephyr\dts\arm\st\f7\stm32f7.dtsi:417 */
		};

		/* node '/soc/can@40006400' defined in zephyr\dts\arm\st\f7\stm32f7.dtsi:420 */
		can1: can@40006400 {
			compatible = "st,stm32-bxcan";             /* in zephyr\dts\arm\st\f7\stm32f7.dtsi:421 */
			reg = < 0x40006400 0x400 >;                /* in zephyr\dts\arm\st\f7\stm32f7.dtsi:422 */
			interrupts = < 0x13 0x0 >,
			             < 0x14 0x0 >,
			             < 0x15 0x0 >,
			             < 0x16 0x0 >;                 /* in zephyr\dts\arm\st\f7\stm32f7.dtsi:423 */
			interrupt-names = "TX",
			                  "RX0",
			                  "RX1",
			                  "SCE";                   /* in zephyr\dts\arm\st\f7\stm32f7.dtsi:424 */
			clocks = < &rcc 0x40 0x2000000 >;          /* in zephyr\dts\arm\st\f7\stm32f7.dtsi:425 */
			pinctrl-0 = < &can1_rx_pd0 &can1_tx_pd1 >; /* in zephyr\boards\st\nucleo_f767zi\nucleo_f767zi.dts:170 */
			pinctrl-names = "default";                 /* in zephyr\boards\st\nucleo_f767zi\nucleo_f767zi.dts:171 */
			status = "okay";                           /* in zephyr\boards\st\nucleo_f767zi\nucleo_f767zi.dts:172 */
		};

		/* node '/soc/timers@40010000' defined in zephyr\dts\arm\st\f7\stm32f7.dtsi:429 */
		timers1: timers@40010000 {
			compatible = "st,stm32-timers"; /* in zephyr\dts\arm\st\f7\stm32f7.dtsi:430 */
			reg = < 0x40010000 0x400 >;     /* in zephyr\dts\arm\st\f7\stm32f7.dtsi:431 */
			clocks = < &rcc 0x44 0x1 >,
			         < &rcc 0xb 0xff >;     /* in zephyr\dts\arm\st\f7\stm32f7.dtsi:432 */
			resets = < &rctl 0x480 >;       /* in zephyr\dts\arm\st\f7\stm32f7.dtsi:434 */
			interrupts = < 0x18 0x0 >,
			             < 0x19 0x0 >,
			             < 0x1a 0x0 >,
			             < 0x1b 0x0 >;      /* in zephyr\dts\arm\st\f7\stm32f7.dtsi:435 */
			interrupt-names = "brk",
			                  "up",
			                  "trgcom",
			                  "cc";         /* in zephyr\dts\arm\st\f7\stm32f7.dtsi:436 */
			st,prescaler = < 0x2710 >;      /* in zephyr\boards\st\nucleo_f767zi\nucleo_f767zi.dts:138 */
			status = "okay";                /* in zephyr\boards\st\nucleo_f767zi\nucleo_f767zi.dts:139 */

			/* node '/soc/timers@40010000/pwm' defined in zephyr\dts\arm\st\f7\stm32f7.dtsi:440 */
			pwm1: pwm {
				compatible = "st,stm32-pwm";    /* in zephyr\dts\arm\st\f7\stm32f7.dtsi:441 */
				#pwm-cells = < 0x3 >;           /* in zephyr\dts\arm\st\f7\stm32f7.dtsi:443 */
				status = "okay";                /* in zephyr\boards\st\nucleo_f767zi\nucleo_f767zi.dts:142 */
				pinctrl-0 = < &tim1_ch3_pe13 >; /* in zephyr\boards\st\nucleo_f767zi\nucleo_f767zi.dts:143 */
				pinctrl-names = "default";      /* in zephyr\boards\st\nucleo_f767zi\nucleo_f767zi.dts:144 */
			};

			/* node '/soc/timers@40010000/qdec' defined in zephyr\dts\arm\st\f7\stm32f7.dtsi:446 */
			qdec {
				compatible = "st,stm32-qdec";    /* in zephyr\dts\arm\st\f7\stm32f7.dtsi:447 */
				st,input-filter-level = < 0x0 >; /* in zephyr\dts\arm\st\f7\stm32f7.dtsi:448 */
				status = "disabled";             /* in zephyr\dts\arm\st\f7\stm32f7.dtsi:449 */
			};
		};

		/* node '/soc/timers@40000000' defined in zephyr\dts\arm\st\f7\stm32f7.dtsi:453 */
		timers2: timers@40000000 {
			compatible = "st,stm32-timers"; /* in zephyr\dts\arm\st\f7\stm32f7.dtsi:454 */
			reg = < 0x40000000 0x400 >;     /* in zephyr\dts\arm\st\f7\stm32f7.dtsi:455 */
			clocks = < &rcc 0x40 0x1 >,
			         < &rcc 0xa 0xff >;     /* in zephyr\dts\arm\st\f7\stm32f7.dtsi:456 */
			resets = < &rctl 0x400 >;       /* in zephyr\dts\arm\st\f7\stm32f7.dtsi:458 */
			interrupts = < 0x1c 0x0 >;      /* in zephyr\dts\arm\st\f7\stm32f7.dtsi:459 */
			interrupt-names = "global";     /* in zephyr\dts\arm\st\f7\stm32f7.dtsi:460 */
			st,prescaler = < 0x0 >;         /* in zephyr\dts\arm\st\f7\stm32f7.dtsi:461 */
			status = "disabled";            /* in zephyr\dts\arm\st\f7\stm32f7.dtsi:462 */

			/* node '/soc/timers@40000000/pwm' defined in zephyr\dts\arm\st\f7\stm32f7.dtsi:464 */
			pwm {
				compatible = "st,stm32-pwm"; /* in zephyr\dts\arm\st\f7\stm32f7.dtsi:465 */
				status = "disabled";         /* in zephyr\dts\arm\st\f7\stm32f7.dtsi:466 */
				#pwm-cells = < 0x3 >;        /* in zephyr\dts\arm\st\f7\stm32f7.dtsi:467 */
			};

			/* node '/soc/timers@40000000/counter' defined in zephyr\dts\arm\st\f7\stm32f7.dtsi:470 */
			counter {
				compatible = "st,stm32-counter"; /* in zephyr\dts\arm\st\f7\stm32f7.dtsi:471 */
				status = "disabled";             /* in zephyr\dts\arm\st\f7\stm32f7.dtsi:472 */
			};

			/* node '/soc/timers@40000000/qdec' defined in zephyr\dts\arm\st\f7\stm32f7.dtsi:475 */
			qdec {
				compatible = "st,stm32-qdec";    /* in zephyr\dts\arm\st\f7\stm32f7.dtsi:476 */
				st,input-filter-level = < 0x0 >; /* in zephyr\dts\arm\st\f7\stm32f7.dtsi:477 */
				status = "disabled";             /* in zephyr\dts\arm\st\f7\stm32f7.dtsi:478 */
			};
		};

		/* node '/soc/timers@40000400' defined in zephyr\dts\arm\st\f7\stm32f7.dtsi:482 */
		timers3: timers@40000400 {
			compatible = "st,stm32-timers"; /* in zephyr\dts\arm\st\f7\stm32f7.dtsi:483 */
			reg = < 0x40000400 0x400 >;     /* in zephyr\dts\arm\st\f7\stm32f7.dtsi:484 */
			clocks = < &rcc 0x40 0x2 >,
			         < &rcc 0xa 0xff >;     /* in zephyr\dts\arm\st\f7\stm32f7.dtsi:485 */
			resets = < &rctl 0x401 >;       /* in zephyr\dts\arm\st\f7\stm32f7.dtsi:487 */
			interrupts = < 0x1d 0x0 >;      /* in zephyr\dts\arm\st\f7\stm32f7.dtsi:488 */
			interrupt-names = "global";     /* in zephyr\dts\arm\st\f7\stm32f7.dtsi:489 */
			st,prescaler = < 0x0 >;         /* in zephyr\dts\arm\st\f7\stm32f7.dtsi:490 */
			status = "disabled";            /* in zephyr\dts\arm\st\f7\stm32f7.dtsi:491 */

			/* node '/soc/timers@40000400/pwm' defined in zephyr\dts\arm\st\f7\stm32f7.dtsi:493 */
			pwm {
				compatible = "st,stm32-pwm"; /* in zephyr\dts\arm\st\f7\stm32f7.dtsi:494 */
				status = "disabled";         /* in zephyr\dts\arm\st\f7\stm32f7.dtsi:495 */
				#pwm-cells = < 0x3 >;        /* in zephyr\dts\arm\st\f7\stm32f7.dtsi:496 */
			};

			/* node '/soc/timers@40000400/counter' defined in zephyr\dts\arm\st\f7\stm32f7.dtsi:499 */
			counter {
				compatible = "st,stm32-counter"; /* in zephyr\dts\arm\st\f7\stm32f7.dtsi:500 */
				status = "disabled";             /* in zephyr\dts\arm\st\f7\stm32f7.dtsi:501 */
			};

			/* node '/soc/timers@40000400/qdec' defined in zephyr\dts\arm\st\f7\stm32f7.dtsi:504 */
			qdec {
				compatible = "st,stm32-qdec";    /* in zephyr\dts\arm\st\f7\stm32f7.dtsi:505 */
				st,input-filter-level = < 0x0 >; /* in zephyr\dts\arm\st\f7\stm32f7.dtsi:506 */
				status = "disabled";             /* in zephyr\dts\arm\st\f7\stm32f7.dtsi:507 */
			};
		};

		/* node '/soc/timers@40000800' defined in zephyr\dts\arm\st\f7\stm32f7.dtsi:511 */
		timers4: timers@40000800 {
			compatible = "st,stm32-timers"; /* in zephyr\dts\arm\st\f7\stm32f7.dtsi:512 */
			reg = < 0x40000800 0x400 >;     /* in zephyr\dts\arm\st\f7\stm32f7.dtsi:513 */
			clocks = < &rcc 0x40 0x4 >,
			         < &rcc 0xa 0xff >;     /* in zephyr\dts\arm\st\f7\stm32f7.dtsi:514 */
			resets = < &rctl 0x402 >;       /* in zephyr\dts\arm\st\f7\stm32f7.dtsi:516 */
			interrupts = < 0x1e 0x0 >;      /* in zephyr\dts\arm\st\f7\stm32f7.dtsi:517 */
			interrupt-names = "global";     /* in zephyr\dts\arm\st\f7\stm32f7.dtsi:518 */
			st,prescaler = < 0x0 >;         /* in zephyr\dts\arm\st\f7\stm32f7.dtsi:519 */
			status = "disabled";            /* in zephyr\dts\arm\st\f7\stm32f7.dtsi:520 */

			/* node '/soc/timers@40000800/pwm' defined in zephyr\dts\arm\st\f7\stm32f7.dtsi:522 */
			pwm {
				compatible = "st,stm32-pwm"; /* in zephyr\dts\arm\st\f7\stm32f7.dtsi:523 */
				status = "disabled";         /* in zephyr\dts\arm\st\f7\stm32f7.dtsi:524 */
				#pwm-cells = < 0x3 >;        /* in zephyr\dts\arm\st\f7\stm32f7.dtsi:525 */
			};

			/* node '/soc/timers@40000800/counter' defined in zephyr\dts\arm\st\f7\stm32f7.dtsi:528 */
			counter {
				compatible = "st,stm32-counter"; /* in zephyr\dts\arm\st\f7\stm32f7.dtsi:529 */
				status = "disabled";             /* in zephyr\dts\arm\st\f7\stm32f7.dtsi:530 */
			};

			/* node '/soc/timers@40000800/qdec' defined in zephyr\dts\arm\st\f7\stm32f7.dtsi:533 */
			qdec {
				compatible = "st,stm32-qdec";    /* in zephyr\dts\arm\st\f7\stm32f7.dtsi:534 */
				st,input-filter-level = < 0x0 >; /* in zephyr\dts\arm\st\f7\stm32f7.dtsi:535 */
				status = "disabled";             /* in zephyr\dts\arm\st\f7\stm32f7.dtsi:536 */
			};
		};

		/* node '/soc/timers@40000c00' defined in zephyr\dts\arm\st\f7\stm32f7.dtsi:540 */
		timers5: timers@40000c00 {
			compatible = "st,stm32-timers"; /* in zephyr\dts\arm\st\f7\stm32f7.dtsi:541 */
			reg = < 0x40000c00 0x400 >;     /* in zephyr\dts\arm\st\f7\stm32f7.dtsi:542 */
			clocks = < &rcc 0x40 0x8 >,
			         < &rcc 0xa 0xff >;     /* in zephyr\dts\arm\st\f7\stm32f7.dtsi:543 */
			resets = < &rctl 0x403 >;       /* in zephyr\dts\arm\st\f7\stm32f7.dtsi:545 */
			interrupts = < 0x32 0x0 >;      /* in zephyr\dts\arm\st\f7\stm32f7.dtsi:546 */
			interrupt-names = "global";     /* in zephyr\dts\arm\st\f7\stm32f7.dtsi:547 */
			st,prescaler = < 0x0 >;         /* in zephyr\dts\arm\st\f7\stm32f7.dtsi:548 */
			status = "disabled";            /* in zephyr\dts\arm\st\f7\stm32f7.dtsi:549 */

			/* node '/soc/timers@40000c00/pwm' defined in zephyr\dts\arm\st\f7\stm32f7.dtsi:551 */
			pwm {
				compatible = "st,stm32-pwm"; /* in zephyr\dts\arm\st\f7\stm32f7.dtsi:552 */
				status = "disabled";         /* in zephyr\dts\arm\st\f7\stm32f7.dtsi:553 */
				#pwm-cells = < 0x3 >;        /* in zephyr\dts\arm\st\f7\stm32f7.dtsi:554 */
			};

			/* node '/soc/timers@40000c00/counter' defined in zephyr\dts\arm\st\f7\stm32f7.dtsi:557 */
			counter {
				compatible = "st,stm32-counter"; /* in zephyr\dts\arm\st\f7\stm32f7.dtsi:558 */
				status = "disabled";             /* in zephyr\dts\arm\st\f7\stm32f7.dtsi:559 */
			};

			/* node '/soc/timers@40000c00/qdec' defined in zephyr\dts\arm\st\f7\stm32f7.dtsi:562 */
			qdec {
				compatible = "st,stm32-qdec";    /* in zephyr\dts\arm\st\f7\stm32f7.dtsi:563 */
				st,input-filter-level = < 0x0 >; /* in zephyr\dts\arm\st\f7\stm32f7.dtsi:564 */
				status = "disabled";             /* in zephyr\dts\arm\st\f7\stm32f7.dtsi:565 */
			};
		};

		/* node '/soc/timers@40001000' defined in zephyr\dts\arm\st\f7\stm32f7.dtsi:569 */
		timers6: timers@40001000 {
			compatible = "st,stm32-timers"; /* in zephyr\dts\arm\st\f7\stm32f7.dtsi:570 */
			reg = < 0x40001000 0x400 >;     /* in zephyr\dts\arm\st\f7\stm32f7.dtsi:571 */
			clocks = < &rcc 0x40 0x10 >,
			         < &rcc 0xa 0xff >;     /* in zephyr\dts\arm\st\f7\stm32f7.dtsi:572 */
			resets = < &rctl 0x404 >;       /* in zephyr\dts\arm\st\f7\stm32f7.dtsi:574 */
			interrupts = < 0x36 0x0 >;      /* in zephyr\dts\arm\st\f7\stm32f7.dtsi:575 */
			interrupt-names = "global";     /* in zephyr\dts\arm\st\f7\stm32f7.dtsi:576 */
			st,prescaler = < 0x0 >;         /* in zephyr\dts\arm\st\f7\stm32f7.dtsi:577 */
			status = "disabled";            /* in zephyr\dts\arm\st\f7\stm32f7.dtsi:578 */

			/* node '/soc/timers@40001000/counter' defined in zephyr\dts\arm\st\f7\stm32f7.dtsi:580 */
			counter {
				compatible = "st,stm32-counter"; /* in zephyr\dts\arm\st\f7\stm32f7.dtsi:581 */
				status = "disabled";             /* in zephyr\dts\arm\st\f7\stm32f7.dtsi:582 */
			};
		};

		/* node '/soc/timers@40001400' defined in zephyr\dts\arm\st\f7\stm32f7.dtsi:586 */
		timers7: timers@40001400 {
			compatible = "st,stm32-timers"; /* in zephyr\dts\arm\st\f7\stm32f7.dtsi:587 */
			reg = < 0x40001400 0x400 >;     /* in zephyr\dts\arm\st\f7\stm32f7.dtsi:588 */
			clocks = < &rcc 0x40 0x20 >,
			         < &rcc 0xa 0xff >;     /* in zephyr\dts\arm\st\f7\stm32f7.dtsi:589 */
			resets = < &rctl 0x405 >;       /* in zephyr\dts\arm\st\f7\stm32f7.dtsi:591 */
			interrupts = < 0x37 0x0 >;      /* in zephyr\dts\arm\st\f7\stm32f7.dtsi:592 */
			interrupt-names = "global";     /* in zephyr\dts\arm\st\f7\stm32f7.dtsi:593 */
			st,prescaler = < 0x0 >;         /* in zephyr\dts\arm\st\f7\stm32f7.dtsi:594 */
			status = "disabled";            /* in zephyr\dts\arm\st\f7\stm32f7.dtsi:595 */

			/* node '/soc/timers@40001400/counter' defined in zephyr\dts\arm\st\f7\stm32f7.dtsi:597 */
			counter {
				compatible = "st,stm32-counter"; /* in zephyr\dts\arm\st\f7\stm32f7.dtsi:598 */
				status = "disabled";             /* in zephyr\dts\arm\st\f7\stm32f7.dtsi:599 */
			};
		};

		/* node '/soc/timers@40010400' defined in zephyr\dts\arm\st\f7\stm32f7.dtsi:603 */
		timers8: timers@40010400 {
			compatible = "st,stm32-timers"; /* in zephyr\dts\arm\st\f7\stm32f7.dtsi:604 */
			reg = < 0x40010400 0x400 >;     /* in zephyr\dts\arm\st\f7\stm32f7.dtsi:605 */
			clocks = < &rcc 0x44 0x2 >,
			         < &rcc 0xb 0xff >;     /* in zephyr\dts\arm\st\f7\stm32f7.dtsi:606 */
			resets = < &rctl 0x481 >;       /* in zephyr\dts\arm\st\f7\stm32f7.dtsi:608 */
			interrupts = < 0x2b 0x0 >,
			             < 0x2c 0x0 >,
			             < 0x2d 0x0 >,
			             < 0x2e 0x0 >;      /* in zephyr\dts\arm\st\f7\stm32f7.dtsi:609 */
			interrupt-names = "brk",
			                  "up",
			                  "trgcom",
			                  "cc";         /* in zephyr\dts\arm\st\f7\stm32f7.dtsi:610 */
			st,prescaler = < 0x0 >;         /* in zephyr\dts\arm\st\f7\stm32f7.dtsi:611 */
			status = "disabled";            /* in zephyr\dts\arm\st\f7\stm32f7.dtsi:612 */

			/* node '/soc/timers@40010400/pwm' defined in zephyr\dts\arm\st\f7\stm32f7.dtsi:614 */
			pwm {
				compatible = "st,stm32-pwm"; /* in zephyr\dts\arm\st\f7\stm32f7.dtsi:615 */
				status = "disabled";         /* in zephyr\dts\arm\st\f7\stm32f7.dtsi:616 */
				#pwm-cells = < 0x3 >;        /* in zephyr\dts\arm\st\f7\stm32f7.dtsi:617 */
			};

			/* node '/soc/timers@40010400/qdec' defined in zephyr\dts\arm\st\f7\stm32f7.dtsi:620 */
			qdec {
				compatible = "st,stm32-qdec";    /* in zephyr\dts\arm\st\f7\stm32f7.dtsi:621 */
				st,input-filter-level = < 0x0 >; /* in zephyr\dts\arm\st\f7\stm32f7.dtsi:622 */
				status = "disabled";             /* in zephyr\dts\arm\st\f7\stm32f7.dtsi:623 */
			};
		};

		/* node '/soc/timers@40014000' defined in zephyr\dts\arm\st\f7\stm32f7.dtsi:627 */
		timers9: timers@40014000 {
			compatible = "st,stm32-timers"; /* in zephyr\dts\arm\st\f7\stm32f7.dtsi:628 */
			reg = < 0x40014000 0x400 >;     /* in zephyr\dts\arm\st\f7\stm32f7.dtsi:629 */
			clocks = < &rcc 0x44 0x10000 >,
			         < &rcc 0xb 0xff >;     /* in zephyr\dts\arm\st\f7\stm32f7.dtsi:630 */
			resets = < &rctl 0x490 >;       /* in zephyr\dts\arm\st\f7\stm32f7.dtsi:632 */
			interrupts = < 0x18 0x0 >;      /* in zephyr\dts\arm\st\f7\stm32f7.dtsi:633 */
			interrupt-names = "global";     /* in zephyr\dts\arm\st\f7\stm32f7.dtsi:634 */
			st,prescaler = < 0x0 >;         /* in zephyr\dts\arm\st\f7\stm32f7.dtsi:635 */
			status = "disabled";            /* in zephyr\dts\arm\st\f7\stm32f7.dtsi:636 */

			/* node '/soc/timers@40014000/pwm' defined in zephyr\dts\arm\st\f7\stm32f7.dtsi:638 */
			pwm {
				compatible = "st,stm32-pwm"; /* in zephyr\dts\arm\st\f7\stm32f7.dtsi:639 */
				status = "disabled";         /* in zephyr\dts\arm\st\f7\stm32f7.dtsi:640 */
				#pwm-cells = < 0x3 >;        /* in zephyr\dts\arm\st\f7\stm32f7.dtsi:641 */
			};

			/* node '/soc/timers@40014000/counter' defined in zephyr\dts\arm\st\f7\stm32f7.dtsi:644 */
			counter {
				compatible = "st,stm32-counter"; /* in zephyr\dts\arm\st\f7\stm32f7.dtsi:645 */
				status = "disabled";             /* in zephyr\dts\arm\st\f7\stm32f7.dtsi:646 */
			};
		};

		/* node '/soc/timers@40014400' defined in zephyr\dts\arm\st\f7\stm32f7.dtsi:650 */
		timers10: timers@40014400 {
			compatible = "st,stm32-timers"; /* in zephyr\dts\arm\st\f7\stm32f7.dtsi:651 */
			reg = < 0x40014400 0x400 >;     /* in zephyr\dts\arm\st\f7\stm32f7.dtsi:652 */
			clocks = < &rcc 0x44 0x20000 >,
			         < &rcc 0xb 0xff >;     /* in zephyr\dts\arm\st\f7\stm32f7.dtsi:653 */
			resets = < &rctl 0x491 >;       /* in zephyr\dts\arm\st\f7\stm32f7.dtsi:655 */
			interrupts = < 0x19 0x0 >;      /* in zephyr\dts\arm\st\f7\stm32f7.dtsi:656 */
			interrupt-names = "global";     /* in zephyr\dts\arm\st\f7\stm32f7.dtsi:657 */
			st,prescaler = < 0x0 >;         /* in zephyr\dts\arm\st\f7\stm32f7.dtsi:658 */
			status = "disabled";            /* in zephyr\dts\arm\st\f7\stm32f7.dtsi:659 */

			/* node '/soc/timers@40014400/pwm' defined in zephyr\dts\arm\st\f7\stm32f7.dtsi:661 */
			pwm {
				compatible = "st,stm32-pwm"; /* in zephyr\dts\arm\st\f7\stm32f7.dtsi:662 */
				status = "disabled";         /* in zephyr\dts\arm\st\f7\stm32f7.dtsi:663 */
				#pwm-cells = < 0x3 >;        /* in zephyr\dts\arm\st\f7\stm32f7.dtsi:664 */
			};

			/* node '/soc/timers@40014400/counter' defined in zephyr\dts\arm\st\f7\stm32f7.dtsi:667 */
			counter {
				compatible = "st,stm32-counter"; /* in zephyr\dts\arm\st\f7\stm32f7.dtsi:668 */
				status = "disabled";             /* in zephyr\dts\arm\st\f7\stm32f7.dtsi:669 */
			};
		};

		/* node '/soc/timers@40014800' defined in zephyr\dts\arm\st\f7\stm32f7.dtsi:673 */
		timers11: timers@40014800 {
			compatible = "st,stm32-timers"; /* in zephyr\dts\arm\st\f7\stm32f7.dtsi:674 */
			reg = < 0x40014800 0x400 >;     /* in zephyr\dts\arm\st\f7\stm32f7.dtsi:675 */
			clocks = < &rcc 0x44 0x40000 >,
			         < &rcc 0xb 0xff >;     /* in zephyr\dts\arm\st\f7\stm32f7.dtsi:676 */
			resets = < &rctl 0x492 >;       /* in zephyr\dts\arm\st\f7\stm32f7.dtsi:678 */
			interrupts = < 0x1a 0x0 >;      /* in zephyr\dts\arm\st\f7\stm32f7.dtsi:679 */
			interrupt-names = "global";     /* in zephyr\dts\arm\st\f7\stm32f7.dtsi:680 */
			st,prescaler = < 0x0 >;         /* in zephyr\dts\arm\st\f7\stm32f7.dtsi:681 */
			status = "disabled";            /* in zephyr\dts\arm\st\f7\stm32f7.dtsi:682 */

			/* node '/soc/timers@40014800/pwm' defined in zephyr\dts\arm\st\f7\stm32f7.dtsi:684 */
			pwm {
				compatible = "st,stm32-pwm"; /* in zephyr\dts\arm\st\f7\stm32f7.dtsi:685 */
				status = "disabled";         /* in zephyr\dts\arm\st\f7\stm32f7.dtsi:686 */
				#pwm-cells = < 0x3 >;        /* in zephyr\dts\arm\st\f7\stm32f7.dtsi:687 */
			};

			/* node '/soc/timers@40014800/counter' defined in zephyr\dts\arm\st\f7\stm32f7.dtsi:690 */
			counter {
				compatible = "st,stm32-counter"; /* in zephyr\dts\arm\st\f7\stm32f7.dtsi:691 */
				status = "disabled";             /* in zephyr\dts\arm\st\f7\stm32f7.dtsi:692 */
			};
		};

		/* node '/soc/timers@40001800' defined in zephyr\dts\arm\st\f7\stm32f7.dtsi:696 */
		timers12: timers@40001800 {
			compatible = "st,stm32-timers"; /* in zephyr\dts\arm\st\f7\stm32f7.dtsi:697 */
			reg = < 0x40001800 0x400 >;     /* in zephyr\dts\arm\st\f7\stm32f7.dtsi:698 */
			clocks = < &rcc 0x40 0x40 >,
			         < &rcc 0xa 0xff >;     /* in zephyr\dts\arm\st\f7\stm32f7.dtsi:699 */
			resets = < &rctl 0x406 >;       /* in zephyr\dts\arm\st\f7\stm32f7.dtsi:701 */
			interrupts = < 0x2b 0x0 >;      /* in zephyr\dts\arm\st\f7\stm32f7.dtsi:702 */
			interrupt-names = "global";     /* in zephyr\dts\arm\st\f7\stm32f7.dtsi:703 */
			st,prescaler = < 0x0 >;         /* in zephyr\dts\arm\st\f7\stm32f7.dtsi:704 */
			status = "disabled";            /* in zephyr\dts\arm\st\f7\stm32f7.dtsi:705 */

			/* node '/soc/timers@40001800/pwm' defined in zephyr\dts\arm\st\f7\stm32f7.dtsi:707 */
			pwm {
				compatible = "st,stm32-pwm"; /* in zephyr\dts\arm\st\f7\stm32f7.dtsi:708 */
				status = "disabled";         /* in zephyr\dts\arm\st\f7\stm32f7.dtsi:709 */
				#pwm-cells = < 0x3 >;        /* in zephyr\dts\arm\st\f7\stm32f7.dtsi:710 */
			};

			/* node '/soc/timers@40001800/counter' defined in zephyr\dts\arm\st\f7\stm32f7.dtsi:713 */
			counter {
				compatible = "st,stm32-counter"; /* in zephyr\dts\arm\st\f7\stm32f7.dtsi:714 */
				status = "disabled";             /* in zephyr\dts\arm\st\f7\stm32f7.dtsi:715 */
			};
		};

		/* node '/soc/timers@40001c00' defined in zephyr\dts\arm\st\f7\stm32f7.dtsi:719 */
		timers13: timers@40001c00 {
			compatible = "st,stm32-timers"; /* in zephyr\dts\arm\st\f7\stm32f7.dtsi:720 */
			reg = < 0x40001c00 0x400 >;     /* in zephyr\dts\arm\st\f7\stm32f7.dtsi:721 */
			clocks = < &rcc 0x40 0x80 >,
			         < &rcc 0xa 0xff >;     /* in zephyr\dts\arm\st\f7\stm32f7.dtsi:722 */
			resets = < &rctl 0x407 >;       /* in zephyr\dts\arm\st\f7\stm32f7.dtsi:724 */
			interrupts = < 0x2c 0x0 >;      /* in zephyr\dts\arm\st\f7\stm32f7.dtsi:725 */
			interrupt-names = "global";     /* in zephyr\dts\arm\st\f7\stm32f7.dtsi:726 */
			st,prescaler = < 0x0 >;         /* in zephyr\dts\arm\st\f7\stm32f7.dtsi:727 */
			status = "disabled";            /* in zephyr\dts\arm\st\f7\stm32f7.dtsi:728 */

			/* node '/soc/timers@40001c00/pwm' defined in zephyr\dts\arm\st\f7\stm32f7.dtsi:730 */
			pwm {
				compatible = "st,stm32-pwm"; /* in zephyr\dts\arm\st\f7\stm32f7.dtsi:731 */
				status = "disabled";         /* in zephyr\dts\arm\st\f7\stm32f7.dtsi:732 */
				#pwm-cells = < 0x3 >;        /* in zephyr\dts\arm\st\f7\stm32f7.dtsi:733 */
			};

			/* node '/soc/timers@40001c00/counter' defined in zephyr\dts\arm\st\f7\stm32f7.dtsi:736 */
			counter {
				compatible = "st,stm32-counter"; /* in zephyr\dts\arm\st\f7\stm32f7.dtsi:737 */
				status = "disabled";             /* in zephyr\dts\arm\st\f7\stm32f7.dtsi:738 */
			};
		};

		/* node '/soc/timers@40002000' defined in zephyr\dts\arm\st\f7\stm32f7.dtsi:742 */
		timers14: timers@40002000 {
			compatible = "st,stm32-timers"; /* in zephyr\dts\arm\st\f7\stm32f7.dtsi:743 */
			reg = < 0x40002000 0x400 >;     /* in zephyr\dts\arm\st\f7\stm32f7.dtsi:744 */
			clocks = < &rcc 0x40 0x100 >,
			         < &rcc 0xa 0xff >;     /* in zephyr\dts\arm\st\f7\stm32f7.dtsi:745 */
			resets = < &rctl 0x408 >;       /* in zephyr\dts\arm\st\f7\stm32f7.dtsi:747 */
			interrupts = < 0x2d 0x0 >;      /* in zephyr\dts\arm\st\f7\stm32f7.dtsi:748 */
			interrupt-names = "global";     /* in zephyr\dts\arm\st\f7\stm32f7.dtsi:749 */
			st,prescaler = < 0x0 >;         /* in zephyr\dts\arm\st\f7\stm32f7.dtsi:750 */
			status = "disabled";            /* in zephyr\dts\arm\st\f7\stm32f7.dtsi:751 */

			/* node '/soc/timers@40002000/pwm' defined in zephyr\dts\arm\st\f7\stm32f7.dtsi:753 */
			pwm {
				compatible = "st,stm32-pwm"; /* in zephyr\dts\arm\st\f7\stm32f7.dtsi:754 */
				status = "disabled";         /* in zephyr\dts\arm\st\f7\stm32f7.dtsi:755 */
				#pwm-cells = < 0x3 >;        /* in zephyr\dts\arm\st\f7\stm32f7.dtsi:756 */
			};

			/* node '/soc/timers@40002000/counter' defined in zephyr\dts\arm\st\f7\stm32f7.dtsi:759 */
			counter {
				compatible = "st,stm32-counter"; /* in zephyr\dts\arm\st\f7\stm32f7.dtsi:760 */
				status = "disabled";             /* in zephyr\dts\arm\st\f7\stm32f7.dtsi:761 */
			};
		};

		/* node '/soc/usb@50000000' defined in zephyr\dts\arm\st\f7\stm32f7.dtsi:765 */
		usbotg_fs: zephyr_udc0: usb@50000000 {
			compatible = "st,stm32-otgfs";                           /* in zephyr\dts\arm\st\f7\stm32f7.dtsi:766 */
			reg = < 0x50000000 0x40000 >;                            /* in zephyr\dts\arm\st\f7\stm32f7.dtsi:767 */
			interrupts = < 0x43 0x0 >;                               /* in zephyr\dts\arm\st\f7\stm32f7.dtsi:768 */
			interrupt-names = "otgfs";                               /* in zephyr\dts\arm\st\f7\stm32f7.dtsi:769 */
			num-bidir-endpoints = < 0x6 >;                           /* in zephyr\dts\arm\st\f7\stm32f7.dtsi:770 */
			ram-size = < 0x500 >;                                    /* in zephyr\dts\arm\st\f7\stm32f7.dtsi:771 */
			maximum-speed = "full-speed";                            /* in zephyr\dts\arm\st\f7\stm32f7.dtsi:772 */
			phys = < &otgfs_phy >;                                   /* in zephyr\dts\arm\st\f7\stm32f7.dtsi:773 */
			clocks = < &rcc 0x34 0x80 >,
			         < &rcc 0x7 0x5b0090 >;                          /* in zephyr\dts\arm\st\f7\stm32f7.dtsi:774 */
			pinctrl-0 = < &usb_otg_fs_dm_pa11 &usb_otg_fs_dp_pa12 >; /* in zephyr\boards\st\nucleo_f767zi\nucleo_f767zi.dts:125 */
			pinctrl-names = "default";                               /* in zephyr\boards\st\nucleo_f767zi\nucleo_f767zi.dts:126 */
			status = "okay";                                         /* in zephyr\boards\st\nucleo_f767zi\nucleo_f767zi.dts:127 */
		};

		/* node '/soc/usb@40040000' defined in zephyr\dts\arm\st\f7\stm32f7.dtsi:779 */
		usbotg_hs: usb@40040000 {
			compatible = "st,stm32-otghs";     /* in zephyr\dts\arm\st\f7\stm32f7.dtsi:780 */
			reg = < 0x40040000 0x40000 >;      /* in zephyr\dts\arm\st\f7\stm32f7.dtsi:781 */
			interrupts = < 0x4d 0x0 >,
			             < 0x4a 0x0 >,
			             < 0x4b 0x0 >;         /* in zephyr\dts\arm\st\f7\stm32f7.dtsi:782 */
			interrupt-names = "otghs",
			                  "ep1_out",
			                  "ep1_in";        /* in zephyr\dts\arm\st\f7\stm32f7.dtsi:783 */
			num-bidir-endpoints = < 0x9 >;     /* in zephyr\dts\arm\st\f7\stm32f7.dtsi:784 */
			ram-size = < 0x1000 >;             /* in zephyr\dts\arm\st\f7\stm32f7.dtsi:785 */
			maximum-speed = "full-speed";      /* in zephyr\dts\arm\st\f7\stm32f7.dtsi:786 */
			clocks = < &rcc 0x30 0x20000000 >,
			         < &rcc 0x7 0x5b0090 >;    /* in zephyr\dts\arm\st\f7\stm32f7.dtsi:787 */
			phys = < &otghs_fs_phy >;          /* in zephyr\dts\arm\st\f7\stm32f7.dtsi:789 */
			status = "disabled";               /* in zephyr\dts\arm\st\f7\stm32f7.dtsi:790 */
		};

		/* node '/soc/rtc@40002800' defined in zephyr\dts\arm\st\f7\stm32f7.dtsi:793 */
		rtc: rtc@40002800 {
			compatible = "st,stm32-rtc";       /* in zephyr\dts\arm\st\f7\stm32f7.dtsi:794 */
			reg = < 0x40002800 0x300 >;        /* in zephyr\dts\arm\st\f7\stm32f7.dtsi:795 */
			interrupts = < 0x29 0x0 >;         /* in zephyr\dts\arm\st\f7\stm32f7.dtsi:796 */
			prescaler = < 0x8000 >;            /* in zephyr\dts\arm\st\f7\stm32f7.dtsi:798 */
			alarms-count = < 0x2 >;            /* in zephyr\dts\arm\st\f7\stm32f7.dtsi:799 */
			alrm-exti-line = < 0x11 >;         /* in zephyr\dts\arm\st\f7\stm32f7.dtsi:800 */
			clocks = < &rcc 0x40 0x10000000 >,
			         < &rcc 0x3 0x10c80070 >;  /* in zephyr\boards\st\nucleo_f767zi\nucleo_f767zi.dts:164 */
			status = "okay";                   /* in zephyr\boards\st\nucleo_f767zi\nucleo_f767zi.dts:166 */

			/* node '/soc/rtc@40002800/backup_regs' defined in zephyr\dts\arm\st\f7\stm32f7.dtsi:803 */
			bbram: backup_regs {
				compatible = "st,stm32-bbram"; /* in zephyr\dts\arm\st\f7\stm32f7.dtsi:804 */
				st,backup-regs = < 0x20 >;     /* in zephyr\dts\arm\st\f7\stm32f7.dtsi:805 */
				status = "disabled";           /* in zephyr\dts\arm\st\f7\stm32f7.dtsi:806 */
			};
		};

		/* node '/soc/adc@40012000' defined in zephyr\dts\arm\st\f7\stm32f7.dtsi:810 */
		adc1: adc@40012000 {
			compatible = "st,stm32f4-adc",
			             "st,stm32-adc";                                 /* in zephyr\dts\arm\st\f7\stm32f7.dtsi:811 */
			reg = < 0x40012000 0x50 >;                                   /* in zephyr\dts\arm\st\f7\stm32f7.dtsi:812 */
			clocks = < &rcc 0x44 0x100 >;                                /* in zephyr\dts\arm\st\f7\stm32f7.dtsi:813 */
			interrupts = < 0x12 0x0 >;                                   /* in zephyr\dts\arm\st\f7\stm32f7.dtsi:814 */
			#io-channel-cells = < 0x1 >;                                 /* in zephyr\dts\arm\st\f7\stm32f7.dtsi:815 */
			resolutions = < 0x607804 0x517804 0x427804 0x337804 >;       /* in zephyr\dts\arm\st\f7\stm32f7.dtsi:816 */
			sampling-times = < 0x3 0xf 0x1c 0x38 0x54 0x70 0x90 0x1e0 >; /* in zephyr\dts\arm\st\f7\stm32f7.dtsi:820 */
			st,adc-sequencer = "FULLY_CONFIGURABLE";                     /* in zephyr\dts\arm\st\f7\stm32f7.dtsi:822 */
			st,adc-oversampler = "OVERSAMPLER_NONE";                     /* in zephyr\dts\arm\st\f7\stm32f7.dtsi:823 */
			st,adc-internal-regulator = "none";                          /* in zephyr\dts\arm\st\f7\stm32f7.dtsi:824 */
			pinctrl-0 = < &adc1_in0_pa0 >;                               /* in zephyr\boards\st\nucleo_f767zi\nucleo_f767zi.dts:176 */
			pinctrl-names = "default";                                   /* in zephyr\boards\st\nucleo_f767zi\nucleo_f767zi.dts:177 */
			st,adc-clock-source = "SYNC";                                /* in zephyr\boards\st\nucleo_f767zi\nucleo_f767zi.dts:178 */
			st,adc-prescaler = < 0x2 >;                                  /* in zephyr\boards\st\nucleo_f767zi\nucleo_f767zi.dts:179 */
			status = "okay";                                             /* in zephyr\boards\st\nucleo_f767zi\nucleo_f767zi.dts:180 */
			phandle = < 0x27 >;                                          /* in zephyr\dts\arm\st\f7\stm32f7.dtsi:936 */
		};

		/* node '/soc/adc@40012100' defined in zephyr\dts\arm\st\f7\stm32f7.dtsi:828 */
		adc2: adc@40012100 {
			compatible = "st,stm32f4-adc",
			             "st,stm32-adc";                                 /* in zephyr\dts\arm\st\f7\stm32f7.dtsi:829 */
			reg = < 0x40012100 0x50 >;                                   /* in zephyr\dts\arm\st\f7\stm32f7.dtsi:830 */
			clocks = < &rcc 0x44 0x200 >;                                /* in zephyr\dts\arm\st\f7\stm32f7.dtsi:831 */
			interrupts = < 0x12 0x0 >;                                   /* in zephyr\dts\arm\st\f7\stm32f7.dtsi:832 */
			#io-channel-cells = < 0x1 >;                                 /* in zephyr\dts\arm\st\f7\stm32f7.dtsi:833 */
			resolutions = < 0x607804 0x517804 0x427804 0x337804 >;       /* in zephyr\dts\arm\st\f7\stm32f7.dtsi:834 */
			sampling-times = < 0x3 0xf 0x1c 0x38 0x54 0x70 0x90 0x1e0 >; /* in zephyr\dts\arm\st\f7\stm32f7.dtsi:838 */
			st,adc-clock-source = "SYNC";                                /* in zephyr\dts\arm\st\f7\stm32f7.dtsi:839 */
			st,adc-sequencer = "FULLY_CONFIGURABLE";                     /* in zephyr\dts\arm\st\f7\stm32f7.dtsi:840 */
			st,adc-oversampler = "OVERSAMPLER_NONE";                     /* in zephyr\dts\arm\st\f7\stm32f7.dtsi:841 */
			st,adc-internal-regulator = "none";                          /* in zephyr\dts\arm\st\f7\stm32f7.dtsi:842 */
			status = "disabled";                                         /* in zephyr\dts\arm\st\f7\stm32f7.dtsi:843 */
		};

		/* node '/soc/adc@40012200' defined in zephyr\dts\arm\st\f7\stm32f7.dtsi:846 */
		adc3: adc@40012200 {
			compatible = "st,stm32f4-adc",
			             "st,stm32-adc";                                 /* in zephyr\dts\arm\st\f7\stm32f7.dtsi:847 */
			reg = < 0x40012200 0x50 >;                                   /* in zephyr\dts\arm\st\f7\stm32f7.dtsi:848 */
			clocks = < &rcc 0x44 0x400 >;                                /* in zephyr\dts\arm\st\f7\stm32f7.dtsi:849 */
			interrupts = < 0x12 0x0 >;                                   /* in zephyr\dts\arm\st\f7\stm32f7.dtsi:850 */
			#io-channel-cells = < 0x1 >;                                 /* in zephyr\dts\arm\st\f7\stm32f7.dtsi:851 */
			resolutions = < 0x607804 0x517804 0x427804 0x337804 >;       /* in zephyr\dts\arm\st\f7\stm32f7.dtsi:852 */
			sampling-times = < 0x3 0xf 0x1c 0x38 0x54 0x70 0x90 0x1e0 >; /* in zephyr\dts\arm\st\f7\stm32f7.dtsi:856 */
			st,adc-clock-source = "SYNC";                                /* in zephyr\dts\arm\st\f7\stm32f7.dtsi:857 */
			st,adc-sequencer = "FULLY_CONFIGURABLE";                     /* in zephyr\dts\arm\st\f7\stm32f7.dtsi:858 */
			st,adc-oversampler = "OVERSAMPLER_NONE";                     /* in zephyr\dts\arm\st\f7\stm32f7.dtsi:859 */
			st,adc-internal-regulator = "none";                          /* in zephyr\dts\arm\st\f7\stm32f7.dtsi:860 */
			status = "disabled";                                         /* in zephyr\dts\arm\st\f7\stm32f7.dtsi:861 */
		};

		/* node '/soc/dac@40007400' defined in zephyr\dts\arm\st\f7\stm32f7.dtsi:864 */
		dac1: dac@40007400 {
			compatible = "st,stm32-dac";       /* in zephyr\dts\arm\st\f7\stm32f7.dtsi:865 */
			reg = < 0x40007400 0x400 >;        /* in zephyr\dts\arm\st\f7\stm32f7.dtsi:866 */
			clocks = < &rcc 0x40 0x20000000 >; /* in zephyr\dts\arm\st\f7\stm32f7.dtsi:867 */
			#io-channel-cells = < 0x1 >;       /* in zephyr\dts\arm\st\f7\stm32f7.dtsi:869 */
			status = "okay";                   /* in zephyr\boards\st\nucleo_f767zi\nucleo_f767zi.dts:184 */
			pinctrl-0 = < &dac_out1_pa4 >;     /* in zephyr\boards\st\nucleo_f767zi\nucleo_f767zi.dts:185 */
			pinctrl-names = "default";         /* in zephyr\boards\st\nucleo_f767zi\nucleo_f767zi.dts:186 */
		};

		/* node '/soc/dma@40026000' defined in zephyr\dts\arm\st\f7\stm32f7.dtsi:872 */
		dma1: dma@40026000 {
			compatible = "st,stm32-dma-v1";                                                      /* in zephyr\dts\arm\st\f7\stm32f7.dtsi:873 */
			#dma-cells = < 0x4 >;                                                                /* in zephyr\dts\arm\st\f7\stm32f7.dtsi:874 */
			reg = < 0x40026000 0x400 >;                                                          /* in zephyr\dts\arm\st\f7\stm32f7.dtsi:875 */
			interrupts = < 0xb 0x0 0xc 0x0 0xd 0x0 0xe 0x0 0xf 0x0 0x10 0x0 0x11 0x0 0x2f 0x0 >; /* in zephyr\dts\arm\st\f7\stm32f7.dtsi:876 */
			clocks = < &rcc 0x30 0x200000 >;                                                     /* in zephyr\dts\arm\st\f7\stm32f7.dtsi:877 */
			status = "disabled";                                                                 /* in zephyr\dts\arm\st\f7\stm32f7.dtsi:878 */
		};

		/* node '/soc/dma@40026400' defined in zephyr\dts\arm\st\f7\stm32f7.dtsi:881 */
		dma2: dma@40026400 {
			compatible = "st,stm32-dma-v1";                                                           /* in zephyr\dts\arm\st\f7\stm32f7.dtsi:882 */
			#dma-cells = < 0x4 >;                                                                     /* in zephyr\dts\arm\st\f7\stm32f7.dtsi:883 */
			reg = < 0x40026400 0x400 >;                                                               /* in zephyr\dts\arm\st\f7\stm32f7.dtsi:884 */
			interrupts = < 0x38 0x0 0x39 0x0 0x3a 0x0 0x3b 0x0 0x3c 0x0 0x44 0x0 0x45 0x0 0x46 0x0 >; /* in zephyr\dts\arm\st\f7\stm32f7.dtsi:885 */
			clocks = < &rcc 0x30 0x400000 >;                                                          /* in zephyr\dts\arm\st\f7\stm32f7.dtsi:886 */
			st,mem2mem;                                                                               /* in zephyr\dts\arm\st\f7\stm32f7.dtsi:887 */
			status = "disabled";                                                                      /* in zephyr\dts\arm\st\f7\stm32f7.dtsi:888 */
		};

		/* node '/soc/rng@50060800' defined in zephyr\dts\arm\st\f7\stm32f7.dtsi:891 */
		rng: rng@50060800 {
			compatible = "st,stm32-rng";    /* in zephyr\dts\arm\st\f7\stm32f7.dtsi:892 */
			reg = < 0x50060800 0x400 >;     /* in zephyr\dts\arm\st\f7\stm32f7.dtsi:893 */
			interrupts = < 0x50 0x0 >;      /* in zephyr\dts\arm\st\f7\stm32f7.dtsi:894 */
			clocks = < &rcc 0x34 0x40 >,
			         < &rcc 0x7 0x5b0090 >; /* in zephyr\dts\arm\st\f7\stm32f7.dtsi:895 */
			status = "okay";                /* in zephyr\boards\st\nucleo_f767zi\nucleo_f767zi.dts:190 */
		};

		/* node '/soc/sdmmc@40012c00' defined in zephyr\dts\arm\st\f7\stm32f7.dtsi:900 */
		sdmmc1: sdmmc@40012c00 {
			compatible = "st,stm32-sdmmc";  /* in zephyr\dts\arm\st\f7\stm32f7.dtsi:901 */
			reg = < 0x40012c00 0x400 >;     /* in zephyr\dts\arm\st\f7\stm32f7.dtsi:902 */
			clocks = < &rcc 0x44 0x800 >,
			         < &rcc 0x7 0x5c0090 >; /* in zephyr\dts\arm\st\f7\stm32f7.dtsi:903 */
			resets = < &rctl 0x48b >;       /* in zephyr\dts\arm\st\f7\stm32f7.dtsi:905 */
			interrupts = < 0x31 0x0 >;      /* in zephyr\dts\arm\st\f7\stm32f7.dtsi:906 */
			status = "disabled";            /* in zephyr\dts\arm\st\f7\stm32f7.dtsi:907 */
		};

		/* node '/soc/memory@40024000' defined in zephyr\dts\arm\st\f7\stm32f7.dtsi:910 */
		backup_sram: memory@40024000 {
			compatible = "zephyr,memory-region",
			             "st,stm32-backup-sram";  /* in zephyr\dts\arm\st\f7\stm32f7.dtsi:911 */
			reg = < 0x40024000 0x1000 >;          /* in zephyr\dts\arm\st\f7\stm32f7.dtsi:912 */
			clocks = < &rcc 0x30 0x40000 >;       /* in zephyr\dts\arm\st\f7\stm32f7.dtsi:913 */
			zephyr,memory-region = "BACKUP_SRAM"; /* in zephyr\dts\arm\st\f7\stm32f7.dtsi:914 */
			status = "disabled";                  /* in zephyr\dts\arm\st\f7\stm32f7.dtsi:915 */
		};

		/* node '/soc/spi@a0001000' defined in zephyr\dts\arm\st\f7\stm32f7.dtsi:918 */
		quadspi: spi@a0001000 {
			compatible = "st,stm32-qspi";    /* in zephyr\dts\arm\st\f7\stm32f7.dtsi:919 */
			#address-cells = < 0x1 >;        /* in zephyr\dts\arm\st\f7\stm32f7.dtsi:920 */
			#size-cells = < 0x0 >;           /* in zephyr\dts\arm\st\f7\stm32f7.dtsi:921 */
			reg = < 0xa0001000 0x1000 >,
			      < 0x90000000 0x10000000 >; /* in zephyr\dts\arm\st\f7\stm32f7.dtsi:922 */
			interrupts = < 0x5c 0x0 >;       /* in zephyr\dts\arm\st\f7\stm32f7.dtsi:923 */
			clocks = < &rcc 0x38 0x2 >;      /* in zephyr\dts\arm\st\f7\stm32f7.dtsi:924 */
			status = "disabled";             /* in zephyr\dts\arm\st\f7\stm32f7.dtsi:925 */
		};

		/* node '/soc/i2c@40006000' defined in zephyr\dts\arm\st\f7\stm32f765.dtsi:49 */
		i2c4: i2c@40006000 {
			compatible = "st,stm32-i2c-v2";   /* in zephyr\dts\arm\st\f7\stm32f765.dtsi:50 */
			clock-frequency = < 0x186a0 >;    /* in zephyr\dts\arm\st\f7\stm32f765.dtsi:51 */
			#address-cells = < 0x1 >;         /* in zephyr\dts\arm\st\f7\stm32f765.dtsi:52 */
			#size-cells = < 0x0 >;            /* in zephyr\dts\arm\st\f7\stm32f765.dtsi:53 */
			reg = < 0x40006000 0x400 >;       /* in zephyr\dts\arm\st\f7\stm32f765.dtsi:54 */
			clocks = < &rcc 0x40 0x1000000 >; /* in zephyr\dts\arm\st\f7\stm32f765.dtsi:55 */
			interrupts = < 0x5f 0x0 >,
			             < 0x60 0x0 >;        /* in zephyr\dts\arm\st\f7\stm32f765.dtsi:56 */
			interrupt-names = "event",
			                  "error";        /* in zephyr\dts\arm\st\f7\stm32f765.dtsi:57 */
			status = "disabled";              /* in zephyr\dts\arm\st\f7\stm32f765.dtsi:58 */
			phandle = < 0x2a >;               /* in zephyr\dts\arm\st\f7\stm32f765.dtsi:111 */
		};

		/* node '/soc/spi@40015400' defined in zephyr\dts\arm\st\f7\stm32f765.dtsi:61 */
		spi6: spi@40015400 {
			compatible = "st,stm32-spi-fifo",
			             "st,stm32-spi";      /* in zephyr\dts\arm\st\f7\stm32f765.dtsi:62 */
			#address-cells = < 0x1 >;         /* in zephyr\dts\arm\st\f7\stm32f765.dtsi:63 */
			#size-cells = < 0x0 >;            /* in zephyr\dts\arm\st\f7\stm32f765.dtsi:64 */
			reg = < 0x40015400 0x400 >;       /* in zephyr\dts\arm\st\f7\stm32f765.dtsi:65 */
			clocks = < &rcc 0x44 0x200000 >;  /* in zephyr\dts\arm\st\f7\stm32f765.dtsi:66 */
			interrupts = < 0x56 0x5 >;        /* in zephyr\dts\arm\st\f7\stm32f765.dtsi:67 */
			status = "disabled";              /* in zephyr\dts\arm\st\f7\stm32f765.dtsi:68 */
		};

		/* node '/soc/ethernet@40028000' defined in zephyr\dts\arm\st\f7\stm32f765.dtsi:71 */
		ethernet@40028000 {
			reg = < 0x40028000 0x8000 >;                 /* in zephyr\dts\arm\st\f7\stm32f765.dtsi:72 */
			compatible = "st,stm32-ethernet-controller"; /* in zephyr\dts\arm\st\f7\stm32f765.dtsi:73 */
			clock-names = "stm-eth";                     /* in zephyr\dts\arm\st\f7\stm32f765.dtsi:74 */
			clocks = < &rcc 0x30 0x2000000 >;            /* in zephyr\dts\arm\st\f7\stm32f765.dtsi:75 */

			/* node '/soc/ethernet@40028000/ethernet' defined in zephyr\dts\arm\st\f7\stm32f765.dtsi:77 */
			mac: ethernet {
				compatible = "st,stm32-ethernet";                                                                         /* in zephyr\dts\arm\st\f7\stm32f765.dtsi:78 */
				interrupts = < 0x3d 0x0 >;                                                                                /* in zephyr\dts\arm\st\f7\stm32f765.dtsi:79 */
				clock-names = "mac-clk-tx",
				              "mac-clk-rx",
				              "mac-clk-ptp";                                                                              /* in zephyr\dts\arm\st\f7\stm32f765.dtsi:80 */
				clocks = < &rcc 0x30 0x4000000 >,
				         < &rcc 0x30 0x8000000 >,
				         < &rcc 0x30 0x10000000 >;                                                                        /* in zephyr\dts\arm\st\f7\stm32f765.dtsi:82 */
				status = "okay";                                                                                          /* in zephyr\boards\st\nucleo_f767zi\nucleo_f767zi.dts:194 */
				pinctrl-0 = < &eth_rxd0_pc4 &eth_rxd1_pc5 &eth_ref_clk_pa1 &eth_crs_dv_pa7 &eth_tx_en_pg11 &eth_txd0_pg13
				              &eth_txd1_pb13 >;                                                                           /* in zephyr\boards\st\nucleo_f767zi\nucleo_f767zi.dts:195 */
				pinctrl-names = "default";                                                                                /* in zephyr\boards\st\nucleo_f767zi\nucleo_f767zi.dts:202 */
				phy-connection-type = "rmii";                                                                             /* in zephyr\boards\st\nucleo_f767zi\nucleo_f767zi.dts:203 */
				phy-handle = < &eth_phy >;                                                                                /* in zephyr\boards\st\nucleo_f767zi\nucleo_f767zi.dts:204 */
			};

			/* node '/soc/ethernet@40028000/mdio' defined in zephyr\dts\arm\st\f7\stm32f765.dtsi:88 */
			mdio: mdio {
				compatible = "st,stm32-mdio";               /* in zephyr\dts\arm\st\f7\stm32f765.dtsi:89 */
				#address-cells = < 0x1 >;                   /* in zephyr\dts\arm\st\f7\stm32f765.dtsi:90 */
				#size-cells = < 0x0 >;                      /* in zephyr\dts\arm\st\f7\stm32f765.dtsi:91 */
				status = "okay";                            /* in zephyr\boards\st\nucleo_f767zi\nucleo_f767zi.dts:208 */
				pinctrl-0 = < &eth_mdio_pa2 &eth_mdc_pc1 >; /* in zephyr\boards\st\nucleo_f767zi\nucleo_f767zi.dts:209 */
				pinctrl-names = "default";                  /* in zephyr\boards\st\nucleo_f767zi\nucleo_f767zi.dts:210 */

				/* node '/soc/ethernet@40028000/mdio/ethernet-phy@0' defined in zephyr\boards\st\nucleo_f767zi\nucleo_f767zi.dts:212 */
				eth_phy: ethernet-phy@0 {
					compatible = "ethernet-phy"; /* in zephyr\boards\st\nucleo_f767zi\nucleo_f767zi.dts:213 */
					reg = < 0x0 >;               /* in zephyr\boards\st\nucleo_f767zi\nucleo_f767zi.dts:214 */
					phandle = < 0x23 >;          /* in zephyr\boards\st\nucleo_f767zi\nucleo_f767zi.dts:204 */
				};
			};
		};

		/* node '/soc/sdmmc@40011c00' defined in zephyr\dts\arm\st\f7\stm32f765.dtsi:96 */
		sdmmc2: sdmmc@40011c00 {
			compatible = "st,stm32-sdmmc";  /* in zephyr\dts\arm\st\f7\stm32f765.dtsi:97 */
			reg = < 0x40011c00 0x400 >;     /* in zephyr\dts\arm\st\f7\stm32f765.dtsi:98 */
			clocks = < &rcc 0x44 0x80 >,
			         < &rcc 0x7 0x5d0090 >; /* in zephyr\dts\arm\st\f7\stm32f765.dtsi:99 */
			resets = < &rctl 0x487 >;       /* in zephyr\dts\arm\st\f7\stm32f765.dtsi:101 */
			interrupts = < 0x67 0x0 >;      /* in zephyr\dts\arm\st\f7\stm32f765.dtsi:102 */
			status = "disabled";            /* in zephyr\dts\arm\st\f7\stm32f765.dtsi:103 */
		};

		/* node '/soc/display-controller@40016800' defined in zephyr\dts\arm\st\f7\stm32f767.dtsi:15 */
		ltdc: display-controller@40016800 {
			compatible = "st,stm32-ltdc";     /* in zephyr\dts\arm\st\f7\stm32f767.dtsi:16 */
			reg = < 0x40016800 0x200 >;       /* in zephyr\dts\arm\st\f7\stm32f767.dtsi:17 */
			interrupts = < 0x58 0x0 >,
			             < 0x59 0x0 >;        /* in zephyr\dts\arm\st\f7\stm32f767.dtsi:18 */
			interrupt-names = "ltdc",
			                  "ltdc_err";     /* in zephyr\dts\arm\st\f7\stm32f767.dtsi:19 */
			clocks = < &rcc 0x44 0x4000000 >; /* in zephyr\dts\arm\st\f7\stm32f767.dtsi:20 */
			resets = < &rctl 0x49a >;         /* in zephyr\dts\arm\st\f7\stm32f767.dtsi:21 */
			status = "disabled";              /* in zephyr\dts\arm\st\f7\stm32f767.dtsi:22 */
		};

		/* node '/soc/dsihost@40016c00' defined in zephyr\dts\arm\st\f7\stm32f767.dtsi:25 */
		mipi_dsi: dsihost@40016c00 {
			compatible = "st,stm32-mipi-dsi"; /* in zephyr\dts\arm\st\f7\stm32f767.dtsi:26 */
			#address-cells = < 0x1 >;         /* in zephyr\dts\arm\st\f7\stm32f767.dtsi:27 */
			#size-cells = < 0x0 >;            /* in zephyr\dts\arm\st\f7\stm32f767.dtsi:28 */
			reg = < 0x40016c00 0x800 >;       /* in zephyr\dts\arm\st\f7\stm32f767.dtsi:29 */
			clock-names = "dsiclk",
			              "refclk",
			              "pixelclk";         /* in zephyr\dts\arm\st\f7\stm32f767.dtsi:30 */
			clocks = < &rcc 0x44 0x8000000 >,
			         < &rcc 0x5 0xff >,
			         < &rcc 0x11 0xff >;      /* in zephyr\dts\arm\st\f7\stm32f767.dtsi:31 */
			resets = < &rctl 0x49b >;         /* in zephyr\dts\arm\st\f7\stm32f767.dtsi:34 */
			status = "disabled";              /* in zephyr\dts\arm\st\f7\stm32f767.dtsi:35 */
		};
	};

	/* node '/cpus' defined in zephyr\dts\arm\st\f7\stm32f7.dtsi:31 */
	cpus {
		#address-cells = < 0x1 >; /* in zephyr\dts\arm\st\f7\stm32f7.dtsi:32 */
		#size-cells = < 0x0 >;    /* in zephyr\dts\arm\st\f7\stm32f7.dtsi:33 */

		/* node '/cpus/cpu@0' defined in zephyr\dts\arm\st\f7\stm32f7.dtsi:35 */
		cpu0: cpu@0 {
			device_type = "cpu";          /* in zephyr\dts\arm\st\f7\stm32f7.dtsi:36 */
			compatible = "arm,cortex-m7"; /* in zephyr\dts\arm\st\f7\stm32f7.dtsi:37 */
			reg = < 0x0 >;                /* in zephyr\dts\arm\st\f7\stm32f7.dtsi:38 */
			#address-cells = < 0x1 >;     /* in zephyr\dts\arm\st\f7\stm32f7.dtsi:39 */
			#size-cells = < 0x1 >;        /* in zephyr\dts\arm\st\f7\stm32f7.dtsi:40 */

			/* node '/cpus/cpu@0/mpu@e000ed90' defined in zephyr\dts\arm\st\f7\stm32f7.dtsi:42 */
			mpu: mpu@e000ed90 {
				compatible = "arm,armv7m-mpu"; /* in zephyr\dts\arm\st\f7\stm32f7.dtsi:43 */
				reg = < 0xe000ed90 0x40 >;     /* in zephyr\dts\arm\st\f7\stm32f7.dtsi:44 */
			};
		};
	};

	/* node '/memory-placeholder@90000000' defined in zephyr\dts\arm\st\f7\stm32f7.dtsi:49 */
	quadspi_memory: memory-placeholder@90000000 {
		compatible = "zephyr,memory-region",
		             "mmio-sram";                  /* in zephyr\dts\arm\st\f7\stm32f7.dtsi:50 */
		reg = < 0x90000000 0x10000000 >;           /* in zephyr\dts\arm\st\f7\stm32f7.dtsi:51 */
		zephyr,memory-region = "QSPI_PLACEHOLDER"; /* in zephyr\dts\arm\st\f7\stm32f7.dtsi:52 */
		zephyr,memory-attr = < 0x2000000 >;        /* in zephyr\dts\arm\st\f7\stm32f7.dtsi:53 */
	};

	/* node '/clocks' defined in zephyr\dts\arm\st\f7\stm32f7.dtsi:56 */
	clocks {

		/* node '/clocks/clk-hse' defined in zephyr\dts\arm\st\f7\stm32f7.dtsi:57 */
		clk_hse: clk-hse {
			#clock-cells = < 0x0 >;            /* in zephyr\dts\arm\st\f7\stm32f7.dtsi:58 */
			compatible = "st,stm32-hse-clock"; /* in zephyr\dts\arm\st\f7\stm32f7.dtsi:59 */
			hse-bypass;                        /* in zephyr\boards\st\nucleo_f767zi\nucleo_f767zi.dts:79 */
			clock-frequency = < 0x7a1200 >;    /* in zephyr\boards\st\nucleo_f767zi\nucleo_f767zi.dts:80 */
			status = "okay";                   /* in zephyr\boards\st\nucleo_f767zi\nucleo_f767zi.dts:81 */
			phandle = < 0x26 >;                /* in zephyr\boards\st\nucleo_f767zi\nucleo_f767zi.dts:89 */
		};

		/* node '/clocks/clk-hsi' defined in zephyr\dts\arm\st\f7\stm32f7.dtsi:63 */
		clk_hsi: clk-hsi {
			#clock-cells = < 0x0 >;         /* in zephyr\dts\arm\st\f7\stm32f7.dtsi:64 */
			compatible = "fixed-clock";     /* in zephyr\dts\arm\st\f7\stm32f7.dtsi:65 */
			clock-frequency = < 0xf42400 >; /* in zephyr\dts\arm\st\f7\stm32f7.dtsi:66 */
			status = "disabled";            /* in zephyr\dts\arm\st\f7\stm32f7.dtsi:67 */
		};

		/* node '/clocks/clk-lse' defined in zephyr\dts\arm\st\f7\stm32f7.dtsi:70 */
		clk_lse: clk-lse {
			#clock-cells = < 0x0 >;            /* in zephyr\dts\arm\st\f7\stm32f7.dtsi:71 */
			compatible = "st,stm32-lse-clock"; /* in zephyr\dts\arm\st\f7\stm32f7.dtsi:72 */
			clock-frequency = < 0x8000 >;      /* in zephyr\dts\arm\st\f7\stm32f7.dtsi:73 */
			driving-capability = < 0x0 >;      /* in zephyr\dts\arm\st\f7\stm32f7.dtsi:74 */
			status = "disabled";               /* in zephyr\dts\arm\st\f7\stm32f7.dtsi:75 */
		};

		/* node '/clocks/clk-lsi' defined in zephyr\dts\arm\st\f7\stm32f7.dtsi:78 */
		clk_lsi: clk-lsi {
			#clock-cells = < 0x0 >;       /* in zephyr\dts\arm\st\f7\stm32f7.dtsi:79 */
			compatible = "fixed-clock";   /* in zephyr\dts\arm\st\f7\stm32f7.dtsi:80 */
			clock-frequency = < 0x7d00 >; /* in zephyr\dts\arm\st\f7\stm32f7.dtsi:81 */
			status = "okay";              /* in zephyr\boards\st\nucleo_f767zi\nucleo_f767zi.dts:75 */
		};

		/* node '/clocks/pll' defined in zephyr\dts\arm\st\f7\stm32f7.dtsi:85 */
		pll: pll {
			#clock-cells = < 0x0 >;              /* in zephyr\dts\arm\st\f7\stm32f7.dtsi:86 */
			compatible = "st,stm32f7-pll-clock"; /* in zephyr\dts\arm\st\f7\stm32f7.dtsi:87 */
			div-m = < 0x4 >;                     /* in zephyr\boards\st\nucleo_f767zi\nucleo_f767zi.dts:85 */
			mul-n = < 0xd8 >;                    /* in zephyr\boards\st\nucleo_f767zi\nucleo_f767zi.dts:86 */
			div-p = < 0x2 >;                     /* in zephyr\boards\st\nucleo_f767zi\nucleo_f767zi.dts:87 */
			div-q = < 0x9 >;                     /* in zephyr\boards\st\nucleo_f767zi\nucleo_f767zi.dts:88 */
			clocks = < &clk_hse >;               /* in zephyr\boards\st\nucleo_f767zi\nucleo_f767zi.dts:89 */
			status = "okay";                     /* in zephyr\boards\st\nucleo_f767zi\nucleo_f767zi.dts:90 */
			phandle = < 0x3 >;                   /* in zephyr\boards\st\nucleo_f767zi\nucleo_f767zi.dts:94 */
		};

		/* node '/clocks/pllsai' defined in zephyr\dts\arm\st\f7\stm32f7.dtsi:91 */
		pllsai: pllsai {
			compatible = "st,stm32fx-pllsai-clock"; /* in zephyr\dts\arm\st\f7\stm32f7.dtsi:92 */
			#clock-cells = < 0x0 >;                 /* in zephyr\dts\arm\st\f7\stm32f7.dtsi:93 */
			status = "disabled";                    /* in zephyr\dts\arm\st\f7\stm32f7.dtsi:94 */
		};
	};

	/* node '/mcos' defined in zephyr\dts\arm\st\f7\stm32f7.dtsi:98 */
	mcos {

		/* node '/mcos/mco1' defined in zephyr\dts\arm\st\f7\stm32f7.dtsi:99 */
		mco1: mco1 {
			compatible = "st,stm32-clock-mco"; /* in zephyr\dts\arm\st\f7\stm32f7.dtsi:100 */
			status = "disabled";               /* in zephyr\dts\arm\st\f7\stm32f7.dtsi:101 */
		};

		/* node '/mcos/mco2' defined in zephyr\dts\arm\st\f7\stm32f7.dtsi:104 */
		mco2: mco2 {
			compatible = "st,stm32-clock-mco"; /* in zephyr\dts\arm\st\f7\stm32f7.dtsi:105 */
			status = "disabled";               /* in zephyr\dts\arm\st\f7\stm32f7.dtsi:106 */
		};
	};

	/* node '/dietemp' defined in zephyr\dts\arm\st\f7\stm32f7.dtsi:929 */
	die_temp: dietemp {
		compatible = "st,stm32-temp-cal"; /* in zephyr\dts\arm\st\f7\stm32f7.dtsi:930 */
		ts-cal1-addr = < 0x1ff0f44c >;    /* in zephyr\dts\arm\st\f7\stm32f7.dtsi:931 */
		ts-cal2-addr = < 0x1ff0f44e >;    /* in zephyr\dts\arm\st\f7\stm32f7.dtsi:932 */
		ts-cal1-temp = < 0x1e >;          /* in zephyr\dts\arm\st\f7\stm32f7.dtsi:933 */
		ts-cal2-temp = < 0x6e >;          /* in zephyr\dts\arm\st\f7\stm32f7.dtsi:934 */
		ts-cal-vrefanalog = < 0xce4 >;    /* in zephyr\dts\arm\st\f7\stm32f7.dtsi:935 */
		io-channels = < &adc1 0x12 >;     /* in zephyr\dts\arm\st\f7\stm32f7.dtsi:936 */
		status = "disabled";              /* in zephyr\dts\arm\st\f7\stm32f7.dtsi:937 */
	};

	/* node '/vref' defined in zephyr\dts\arm\st\f7\stm32f7.dtsi:940 */
	vref: vref {
		compatible = "st,stm32-vref";      /* in zephyr\dts\arm\st\f7\stm32f7.dtsi:941 */
		vrefint-cal-addr = < 0x1ff0f44a >; /* in zephyr\dts\arm\st\f7\stm32f7.dtsi:942 */
		vrefint-cal-mv = < 0xce4 >;        /* in zephyr\dts\arm\st\f7\stm32f7.dtsi:943 */
		io-channels = < &adc1 0x11 >;      /* in zephyr\dts\arm\st\f7\stm32f7.dtsi:944 */
		status = "okay";                   /* in zephyr\boards\st\nucleo_f767zi\nucleo_f767zi.dts:275 */
	};

	/* node '/vbat' defined in zephyr\dts\arm\st\f7\stm32f7.dtsi:948 */
	vbat: vbat {
		compatible = "st,stm32-vbat"; /* in zephyr\dts\arm\st\f7\stm32f7.dtsi:949 */
		ratio = < 0x4 >;              /* in zephyr\dts\arm\st\f7\stm32f7.dtsi:950 */
		io-channels = < &adc1 0x12 >; /* in zephyr\dts\arm\st\f7\stm32f7.dtsi:951 */
		status = "okay";              /* in zephyr\boards\st\nucleo_f767zi\nucleo_f767zi.dts:279 */
	};

	/* node '/otghs_fs_phy' defined in zephyr\dts\arm\st\f7\stm32f7.dtsi:955 */
	otghs_fs_phy: otghs_fs_phy {
		compatible = "usb-nop-xceiv"; /* in zephyr\dts\arm\st\f7\stm32f7.dtsi:956 */
		#phy-cells = < 0x0 >;         /* in zephyr\dts\arm\st\f7\stm32f7.dtsi:957 */
		phandle = < 0x19 >;           /* in zephyr\dts\arm\st\f7\stm32f7.dtsi:789 */
	};

	/* node '/otgfs_phy' defined in zephyr\dts\arm\st\f7\stm32f7.dtsi:960 */
	otgfs_phy: otgfs_phy {
		compatible = "usb-nop-xceiv"; /* in zephyr\dts\arm\st\f7\stm32f7.dtsi:961 */
		#phy-cells = < 0x0 >;         /* in zephyr\dts\arm\st\f7\stm32f7.dtsi:962 */
		phandle = < 0x16 >;           /* in zephyr\dts\arm\st\f7\stm32f7.dtsi:773 */
	};

	/* node '/smbus1' defined in zephyr\dts\arm\st\f7\stm32f7.dtsi:965 */
	smbus1: smbus1 {
		compatible = "st,stm32-smbus"; /* in zephyr\dts\arm\st\f7\stm32f7.dtsi:966 */
		#address-cells = < 0x1 >;      /* in zephyr\dts\arm\st\f7\stm32f7.dtsi:967 */
		#size-cells = < 0x0 >;         /* in zephyr\dts\arm\st\f7\stm32f7.dtsi:968 */
		i2c = < &i2c2 >;               /* in zephyr\dts\arm\st\f7\stm32f7.dtsi:969 */
		status = "disabled";           /* in zephyr\dts\arm\st\f7\stm32f7.dtsi:970 */
	};

	/* node '/smbus2' defined in zephyr\dts\arm\st\f7\stm32f7.dtsi:973 */
	smbus2: smbus2 {
		compatible = "st,stm32-smbus"; /* in zephyr\dts\arm\st\f7\stm32f7.dtsi:974 */
		#address-cells = < 0x1 >;      /* in zephyr\dts\arm\st\f7\stm32f7.dtsi:975 */
		#size-cells = < 0x0 >;         /* in zephyr\dts\arm\st\f7\stm32f7.dtsi:976 */
		i2c = < &i2c2 >;               /* in zephyr\dts\arm\st\f7\stm32f7.dtsi:977 */
		status = "disabled";           /* in zephyr\dts\arm\st\f7\stm32f7.dtsi:978 */
	};

	/* node '/smbus3' defined in zephyr\dts\arm\st\f7\stm32f7.dtsi:981 */
	smbus3: smbus3 {
		compatible = "st,stm32-smbus"; /* in zephyr\dts\arm\st\f7\stm32f7.dtsi:982 */
		#address-cells = < 0x1 >;      /* in zephyr\dts\arm\st\f7\stm32f7.dtsi:983 */
		#size-cells = < 0x0 >;         /* in zephyr\dts\arm\st\f7\stm32f7.dtsi:984 */
		i2c = < &i2c3 >;               /* in zephyr\dts\arm\st\f7\stm32f7.dtsi:985 */
		status = "disabled";           /* in zephyr\dts\arm\st\f7\stm32f7.dtsi:986 */
	};

	/* node '/memory@20020000' defined in zephyr\dts\arm\st\f7\stm32f765.dtsi:14 */
	sram0: memory@20020000 {
		compatible = "zephyr,memory-region",
		             "mmio-sram";            /* in zephyr\dts\arm\st\f7\stm32f765.dtsi:15 */
		reg = < 0x20020000 0x60000 >;        /* in zephyr\dts\arm\st\f7\stm32f765.dtsi:16 */
		zephyr,memory-region = "SRAM0";      /* in zephyr\dts\arm\st\f7\stm32f765.dtsi:17 */
	};

	/* node '/memory@20000000' defined in zephyr\dts\arm\st\f7\stm32f765.dtsi:20 */
	dtcm: memory@20000000 {
		compatible = "zephyr,memory-region",
		             "arm,dtcm";             /* in zephyr\dts\arm\st\f7\stm32f765.dtsi:21 */
		reg = < 0x20000000 0x20000 >;        /* in zephyr\dts\arm\st\f7\stm32f765.dtsi:22 */
		zephyr,memory-region = "DTCM";       /* in zephyr\dts\arm\st\f7\stm32f765.dtsi:23 */
	};

	/* node '/smbus4' defined in zephyr\dts\arm\st\f7\stm32f765.dtsi:107 */
	smbus4: smbus4 {
		compatible = "st,stm32-smbus"; /* in zephyr\dts\arm\st\f7\stm32f765.dtsi:108 */
		#address-cells = < 0x1 >;      /* in zephyr\dts\arm\st\f7\stm32f765.dtsi:109 */
		#size-cells = < 0x0 >;         /* in zephyr\dts\arm\st\f7\stm32f765.dtsi:110 */
		i2c = < &i2c4 >;               /* in zephyr\dts\arm\st\f7\stm32f765.dtsi:111 */
		status = "disabled";           /* in zephyr\dts\arm\st\f7\stm32f765.dtsi:112 */
	};

	/* node '/connector' defined in zephyr\boards\st\nucleo_f767zi\arduino_r3_connector.dtsi:10 */
	arduino_header: connector {
		compatible = "arduino-header-r3";          /* in zephyr\boards\st\nucleo_f767zi\arduino_r3_connector.dtsi:11 */
		#gpio-cells = < 0x2 >;                     /* in zephyr\boards\st\nucleo_f767zi\arduino_r3_connector.dtsi:12 */
		gpio-map-mask = < 0xffffffff 0xffffffc0 >; /* in zephyr\boards\st\nucleo_f767zi\arduino_r3_connector.dtsi:13 */
		gpio-map-pass-thru = < 0x0 0x3f >;         /* in zephyr\boards\st\nucleo_f767zi\arduino_r3_connector.dtsi:14 */
		gpio-map = < 0x0 0x0 &gpioa 0x3 0x0 >,
		           < 0x1 0x0 &gpioc 0x0 0x0 >,
		           < 0x2 0x0 &gpioc 0x3 0x0 >,
		           < 0x3 0x0 &gpiof 0x3 0x0 >,
		           < 0x4 0x0 &gpiof 0x5 0x0 >,
		           < 0x5 0x0 &gpiof 0xa 0x0 >,
		           < 0x6 0x0 &gpiog 0x9 0x0 >,
		           < 0x7 0x0 &gpiog 0xe 0x0 >,
		           < 0x8 0x0 &gpiof 0xf 0x0 >,
		           < 0x9 0x0 &gpioe 0xd 0x0 >,
		           < 0xa 0x0 &gpiof 0xe 0x0 >,
		           < 0xb 0x0 &gpioe 0xb 0x0 >,
		           < 0xc 0x0 &gpioe 0x9 0x0 >,
		           < 0xd 0x0 &gpiof 0xd 0x0 >,
		           < 0xe 0x0 &gpiof 0xc 0x0 >,
		           < 0xf 0x0 &gpiod 0xf 0x0 >,
		           < 0x10 0x0 &gpiod 0xe 0x0 >,
		           < 0x11 0x0 &gpioa 0x7 0x0 >,
		           < 0x12 0x0 &gpioa 0x6 0x0 >,
		           < 0x13 0x0 &gpioa 0x5 0x0 >,
		           < 0x14 0x0 &gpiob 0x9 0x0 >,
		           < 0x15 0x0 &gpiob 0x8 0x0 >;    /* in zephyr\boards\st\nucleo_f767zi\arduino_r3_connector.dtsi:15 */
	};

	/* node '/leds' defined in zephyr\boards\st\nucleo_f767zi\nucleo_f767zi.dts:34 */
	leds: leds {
		compatible = "gpio-leds"; /* in zephyr\boards\st\nucleo_f767zi\nucleo_f767zi.dts:35 */

		/* node '/leds/led_0' defined in zephyr\boards\st\nucleo_f767zi\nucleo_f767zi.dts:37 */
		green_led: led_0 {
			gpios = < &gpiob 0x0 0x0 >; /* in zephyr\boards\st\nucleo_f767zi\nucleo_f767zi.dts:38 */
			label = "User LD1";         /* in zephyr\boards\st\nucleo_f767zi\nucleo_f767zi.dts:39 */
		};

		/* node '/leds/led_1' defined in zephyr\boards\st\nucleo_f767zi\nucleo_f767zi.dts:42 */
		blue_led: led_1 {
			gpios = < &gpiob 0x7 0x0 >; /* in zephyr\boards\st\nucleo_f767zi\nucleo_f767zi.dts:43 */
			label = "User LD2";         /* in zephyr\boards\st\nucleo_f767zi\nucleo_f767zi.dts:44 */
		};

		/* node '/leds/led_2' defined in zephyr\boards\st\nucleo_f767zi\nucleo_f767zi.dts:47 */
		red_led: led_2 {
			gpios = < &gpiob 0xe 0x0 >; /* in zephyr\boards\st\nucleo_f767zi\nucleo_f767zi.dts:48 */
			label = "User LD3";         /* in zephyr\boards\st\nucleo_f767zi\nucleo_f767zi.dts:49 */
		};
	};

	/* node '/gpio_keys' defined in zephyr\boards\st\nucleo_f767zi\nucleo_f767zi.dts:53 */
	gpio_keys {
		compatible = "gpio-keys"; /* in zephyr\boards\st\nucleo_f767zi\nucleo_f767zi.dts:54 */

		/* node '/gpio_keys/button_0' defined in zephyr\boards\st\nucleo_f767zi\nucleo_f767zi.dts:56 */
		user_button: button_0 {
			label = "User";             /* in zephyr\boards\st\nucleo_f767zi\nucleo_f767zi.dts:57 */
			gpios = < &gpioc 0xd 0x1 >; /* in zephyr\boards\st\nucleo_f767zi\nucleo_f767zi.dts:58 */
			zephyr,code = < 0xb >;      /* in zephyr\boards\st\nucleo_f767zi\nucleo_f767zi.dts:59 */
		};
	};
};
